VERSION ""

NS_ :

BS_:

BU_:

BO_ 1038 ID_1038: 8 Vector__XXX
 SG_ electricalRPM_erpm : 7|32@0+ (1,0) [0|4294967295] "rpm" Vector__XXX
 SG_ dutyCycle_percent : 39|16@0+ (0.1,0) [0.0|6553.5] "%" Vector__XXX
 SG_ inputInverterVoltage_V : 55|16@0+ (1,0) [0|65535] "V" Vector__XXX

BO_ 1070 ID_1070: 8 Vector__XXX
 SG_ motorCurrentPeakToPeak_A : 7|16@0+ (0.1,0) [0.0|6553.5] "A" Vector__XXX
 SG_ batteryCurrent_A : 23|16@0+ (0.1,0) [0.0|6553.5] "A" Vector__XXX

BO_ 1102 ID_1102: 8 Vector__XXX
 SG_ ControllerTemp_C : 7|16@0+ (0.1,0) [0.0|6553.5] "C" Vector__XXX
 SG_ motorTemp_C : 23|16@0+ (0.1,0) [0.0|6553.5] "C" Vector__XXX
 SG_ faultCode : 39|8@0+ (1,0) [0|255] "" Vector__XXX

BO_ 1134 ID_1134: 8 Vector__XXX
 SG_ idPeakToPeak_A : 7|32@0+ (0.01,0) [0.0|42949672.95] "A" Vector__XXX
 SG_ iqPeakToPeak_A : 39|32@0+ (0.01,0) [0.0|42949672.95] "A" Vector__XXX

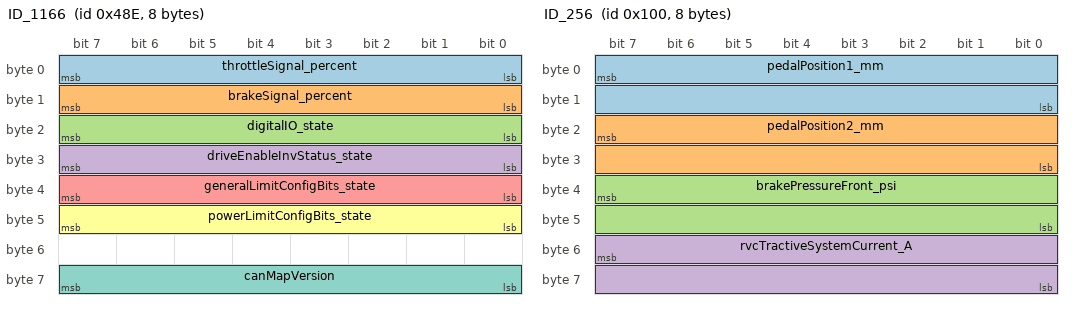
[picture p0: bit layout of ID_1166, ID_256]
BO_ 1166 ID_1166: 8 Vector__XXX
 SG_ throttleSignal_percent : 7|8@0+ (1,0) [0|255] "%" Vector__XXX
 SG_ brakeSignal_percent : 15|8@0+ (1,0) [0|255] "%" Vector__XXX
 SG_ digitalIO_state : 23|8@0+ (1,0) [0|255] "" Vector__XXX
 SG_ driveEnableInvStatus_state : 31|8@0+ (1,0) [0|255] "" Vector__XXX
 SG_ generalLimitConfigBits_state : 39|8@0+ (1,0) [0|255] "" Vector__XXX
 SG_ powerLimitConfigBits_state : 47|8@0+ (1,0) [0|255] "" Vector__XXX
 SG_ canMapVersion : 63|8@0+ (1,0) [0|255] "" Vector__XXX

BO_ 46 ID_46: 8 Vector__XXX
 SG_ desiredInvCurrentPeak_A : 7|16@0+ (0.1,0) [0.0|6553.5] "A" Vector__XXX

BO_ 270 ID_270: 8 Vector__XXX
 SG_ maxCurrentLimitPeak_A : 7|16@0+ (0.1,0) [0.0|6553.5] "A" Vector__XXX

BO_ 334 ID_334: 8 Vector__XXX
 SG_ maxDCCurrentLimit_A : 7|16@0+ (0.1,0) [0.0|6553.5] "A" Vector__XXX

BO_ 398 ID_398: 8 Vector__XXX
 SG_ driveEnable_state : 7|8@0+ (1,0) [0|255] "A" Vector__XXX

BO_ 256 ID_256: 8 Vector__XXX
 SG_ pedalPosition1_mm : 7|16@0+ (0.00610500611,0) [0.0|400.09157541885] "mm" Vector__XXX
 SG_ pedalPosition2_mm : 23|16@0+ (0.00610500611,0) [0.0|400.09157541885] "mm" Vector__XXX
 SG_ brakePressureFront_psi : 39|16@0+ (0.488400488,0) [0.0|32007.32598108] "psi" Vector__XXX
 SG_ rvcTractiveSystemCurrent_A : 55|16@0+ (0.00914627595,-18.727) [-18.727|580.67419438325] "A" Vector__XXX

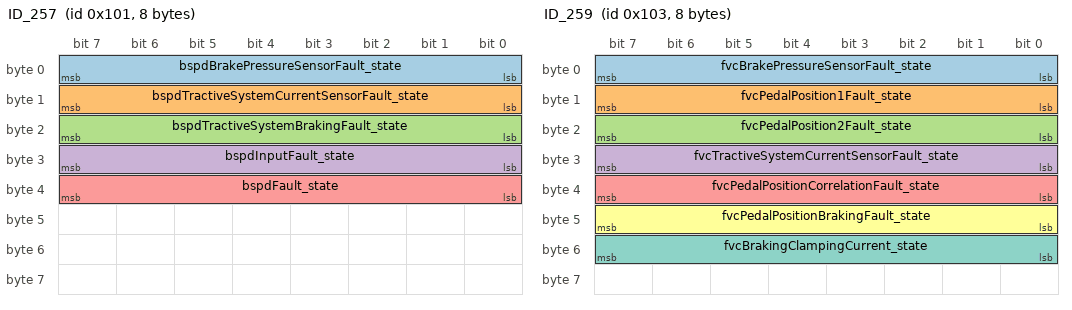
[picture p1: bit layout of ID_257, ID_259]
BO_ 257 ID_257: 8 Vector__XXX
 SG_ bspdBrakePressureSensorFault_state : 7|8@0+ (1,0) [0|255] "" Vector__XXX
 SG_ bspdTractiveSystemCurrentSensorFault_state : 15|8@0+ (1,0) [0|255] "" Vector__XXX
 SG_ bspdTractiveSystemBrakingFault_state : 23|8@0+ (1,0) [0|255] "" Vector__XXX
 SG_ bspdInputFault_state : 31|8@0+ (1,0) [0|255] "" Vector__XXX
 SG_ bspdFault_state : 39|8@0+ (1,0) [0|255] "" Vector__XXX

BO_ 258 ID_258: 8 Vector__XXX
 SG_ pedalPosition1_percent : 7|16@0+ (0.1,0) [0.0|6553.5] "%" Vector__XXX
 SG_ pedalPosition2_percent : 23|16@0+ (0.1,0) [0.0|6553.5] "%" Vector__XXX
 SG_ rideHeightFront_mm : 39|16@0+ (1,0) [0|65535] "mm" Vector__XXX

BO_ 259 ID_259: 8 Vector__XXX
 SG_ fvcBrakePressureSensorFault_state : 7|8@0+ (1,0) [0|255] "" Vector__XXX
 SG_ fvcPedalPosition1Fault_state : 15|8@0+ (1,0) [0|255] "" Vector__XXX
 SG_ fvcPedalPosition2Fault_state : 23|8@0+ (1,0) [0|255] "" Vector__XXX
 SG_ fvcTractiveSystemCurrentSensorFault_state : 31|8@0+ (1,0) [0|255] "" Vector__XXX
 SG_ fvcPedalPositionCorrelationFault_state : 39|8@0+ (1,0) [0|255] "" Vector__XXX
 SG_ fvcPedalPositionBrakingFault_state : 47|8@0+ (1,0) [0|255] "" Vector__XXX
 SG_ fvcBrakingClampingCurrent_state : 55|8@0+ (1,0) [0|255] "" Vector__XXX

BO_ 260 ID_260: 8 Vector__XXX
 SG_ coolantPumpPressure_psi : 7|16@0+ (0.0244200244,0) [0.0|1600.3662990540001] "psi" Vector__XXX
 SG_ coolantFanPower_percent : 23|8@0+ (1,0) [0|255] "%" Vector__XXX
 SG_ coolantPumpPower_percent : 31|8@0+ (1,0) [0|255] "%" Vector__XXX

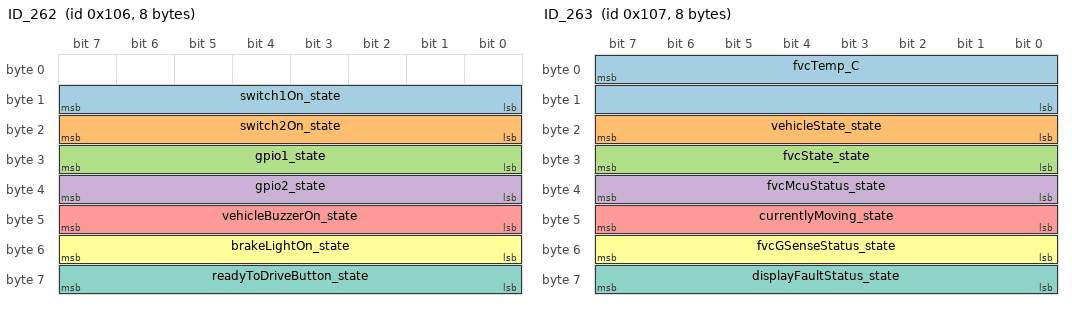
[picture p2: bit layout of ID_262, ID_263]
BO_ 262 ID_262: 8 Vector__XXX
 SG_ switch1On_state : 15|8@0+ (1,0) [0|255] "" Vector__XXX
 SG_ switch2On_state : 23|8@0+ (1,0) [0|255] "" Vector__XXX
 SG_ gpio1_state : 31|8@0+ (1,0) [0|255] "" Vector__XXX
 SG_ gpio2_state : 39|8@0+ (1,0) [0|255] "" Vector__XXX
 SG_ vehicleBuzzerOn_state : 47|8@0+ (1,0) [0|255] "" Vector__XXX
 SG_ brakeLightOn_state : 55|8@0+ (1,0) [0|255] "" Vector__XXX
 SG_ readyToDriveButton_state : 63|8@0+ (1,0) [0|255] "" Vector__XXX

BO_ 263 ID_263: 8 Vector__XXX
 SG_ fvcTemp_C : 7|16@0+ (0.1,0) [0.0|6553.5] "C" Vector__XXX
 SG_ vehicleState_state : 23|8@0+ (1,0) [0|255] "" Vector__XXX
 SG_ fvcState_state : 31|8@0+ (1,0) [0|255] "" Vector__XXX
 SG_ fvcMcuStatus_state : 39|8@0+ (1,0) [0|255] "" Vector__XXX
 SG_ currentlyMoving_state : 47|8@0+ (1,0) [0|255] "" Vector__XXX
 SG_ fvcGSenseStatus_state : 55|8@0+ (1,0) [0|255] "" Vector__XXX
 SG_ displayFaultStatus_state : 63|8@0+ (1,0) [0|255] "" Vector__XXX

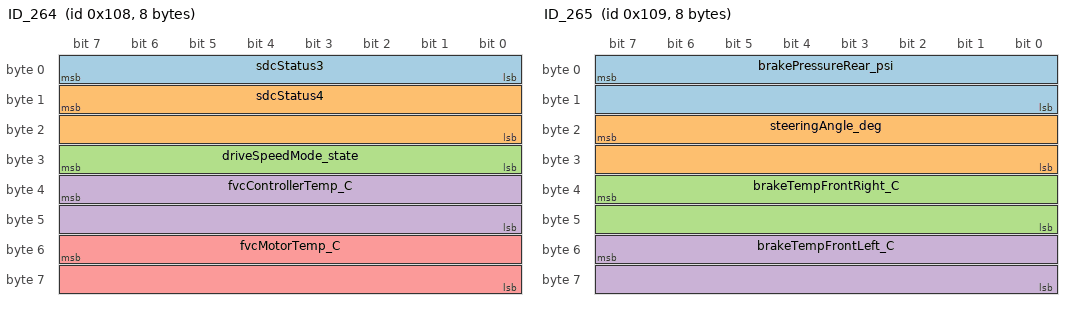
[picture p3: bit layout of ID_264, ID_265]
BO_ 264 ID_264: 8 Vector__XXX
 SG_ sdcStatus3 : 7|8@0+ (1,0) [0|255] "" Vector__XXX
 SG_ sdcStatus4 : 15|16@0+ (1,0) [0|65535] "" Vector__XXX
 SG_ driveSpeedMode_state : 31|8@0+ (1,0) [0|255] "" Vector__XXX
 SG_ fvcControllerTemp_C : 39|16@0+ (1,0) [0|65535] "C" Vector__XXX
 SG_ fvcMotorTemp_C : 55|16@0+ (1,0) [0|65535] "C" Vector__XXX

BO_ 265 ID_265: 8 Vector__XXX
 SG_ brakePressureRear_psi : 7|16@0+ (0.488400488,0) [0.0|32007.32598108] "psi" Vector__XXX
 SG_ steeringAngle_deg : 23|16@0+ (0.01,0) [0.0|655.35] "deg" Vector__XXX
 SG_ brakeTempFrontRight_C : 39|16@0+ (0.195360195,0) [0.0|12802.930379324998] "C" Vector__XXX
 SG_ brakeTempFrontLeft_C : 55|16@0+ (0.195360195,0) [0.0|12802.930379324998] "C" Vector__XXX

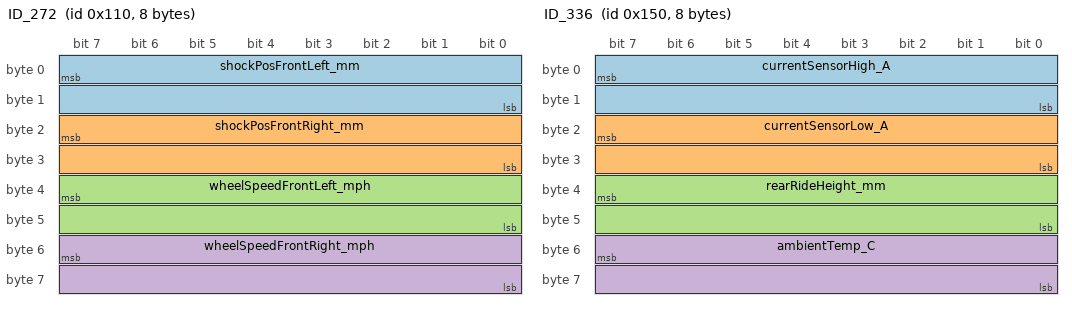
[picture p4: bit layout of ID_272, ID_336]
BO_ 272 ID_272: 8 Vector__XXX
 SG_ shockPosFrontLeft_mm : 7|16@0+ (0.01221001221,0) [0.0|800.18315018235] "mm" Vector__XXX
 SG_ shockPosFrontRight_mm : 23|16@0+ (0.01221001221,0) [0.0|800.18315018235] "mm" Vector__XXX
 SG_ wheelSpeedFrontLeft_mph : 39|16@0+ (0.01,0) [0.0|655.35] "mph" Vector__XXX
 SG_ wheelSpeedFrontRight_mph : 55|16@0+ (0.01,0) [0.0|655.35] "mph" Vector__XXX

BO_ 273 ID_273: 8 Vector__XXX
 SG_ pittoTubePressure_psi : 7|16@0+ (0.01,0) [0.0|655.35] "psi" Vector__XXX

BO_ 288 ID_288: 8 Vector__XXX
 SG_ fvcPowerCycleNeeded : 7|8@0+ (1,0) [0|255] "" Vector__XXX

BO_ 336 ID_336: 8 Vector__XXX
 SG_ currentSensorHigh_A : 7|16@0+ (0.1,-1000) [-1000.0|5553.5] "V" Vector__XXX
 SG_ currentSensorLow_A : 23|16@0+ (0.01,-100) [-100.0|555.35] "V" Vector__XXX
 SG_ rearRideHeight_mm : 39|16@0+ (1,0) [0|65535] "mm" Vector__XXX
 SG_ ambientTemp_C : 55|16@0+ (1,0) [0|65535] "C" Vector__XXX

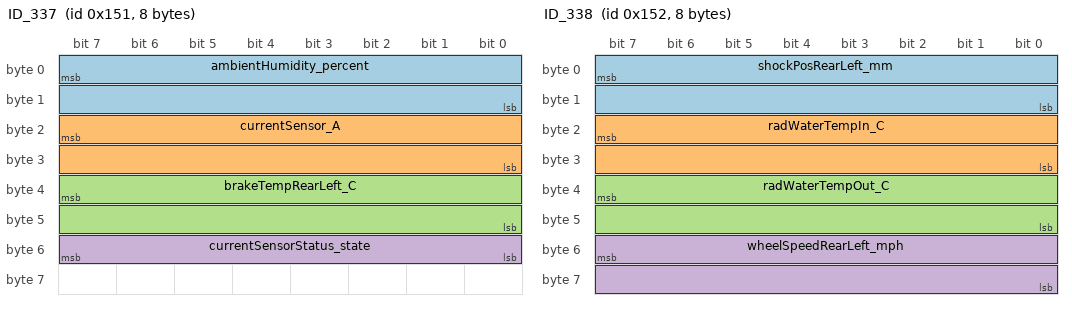
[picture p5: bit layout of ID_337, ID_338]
BO_ 337 ID_337: 8 Vector__XXX
 SG_ ambientHumidity_percent : 7|16@0+ (0.00152590218,0) [0.0|99.99999936629999] "%" Vector__XXX
 SG_ currentSensor_A : 23|16@0+ (0.01414511329,75) [75.0|1001.99999946015] "A" Vector__XXX
 SG_ brakeTempRearLeft_C : 39|16@0+ (0.195360195,0) [0.0|12802.930379324998] "C" Vector__XXX
 SG_ currentSensorStatus_state : 55|8@0+ (1,0) [0|255] "A" Vector__XXX

BO_ 338 ID_338: 8 Vector__XXX
 SG_ shockPosRearLeft_mm : 7|16@0+ (0.01221001221,0) [0.0|800.18315018235] "mm" Vector__XXX
 SG_ radWaterTempIn_C : 23|16@0+ (0.0488400488,0) [0.0|3200.7325981080003] "C" Vector__XXX
 SG_ radWaterTempOut_C : 39|16@0+ (0.0488400488,0) [0.0|3200.7325981080003] "C" Vector__XXX
 SG_ wheelSpeedRearLeft_mph : 55|16@0+ (0.002288853283971548,0) [0.0|149.9999999650754] "mph" Vector__XXX

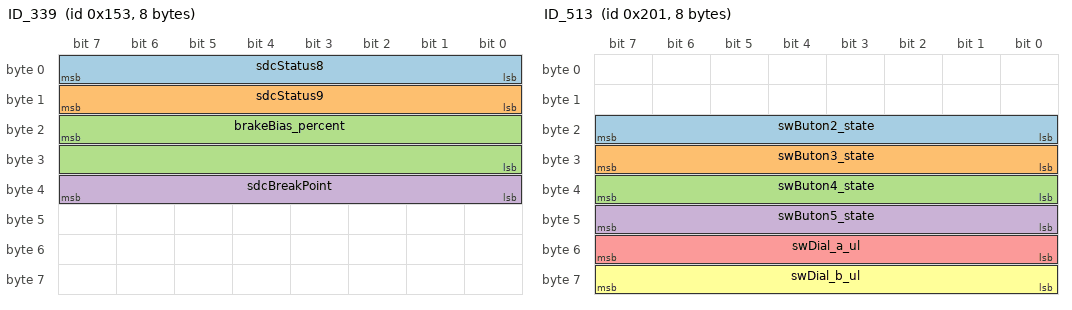
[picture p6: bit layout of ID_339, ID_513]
BO_ 339 ID_339: 8 Vector__XXX
 SG_ sdcStatus8 : 7|8@0+ (1,0) [0|255] "" Vector__XXX
 SG_ sdcStatus9 : 15|8@0+ (1,0) [0|255] "" Vector__XXX
 SG_ brakeBias_percent : 23|16@0+ (1,0) [0|65535] "" Vector__XXX
 SG_ sdcBreakPoint : 39|8@0+ (1,0) [0|255] "" Vector__XXX

BO_ 340 ID_340: 8 Vector__XXX
 SG_ brakeTempRearRight_C : 7|16@0+ (0.195360195,0) [0.0|12802.930379324998] "C" Vector__XXX
 SG_ shockPosRearRight_mm : 23|16@0+ (0.01221001221,0) [0.0|800.18315018235] "mm" Vector__XXX
 SG_ wheelSpeedRearRight_mph : 39|16@0+ (0.002288853283971548,0) [0.0|149.9999999650754] "mph" Vector__XXX

BO_ 341 ID_341: 8 Vector__XXX
 SG_ sdcStatus5 : 7|8@0+ (1,0) [0|255] "" Vector__XXX
 SG_ sdcStatus6 : 15|8@0+ (1,0) [0|255] "" Vector__XXX
 SG_ sdcStatus7 : 23|8@0+ (1,0) [0|255] "" Vector__XXX

BO_ 512 ID_512: 8 Vector__XXX
 SG_ swButon0_state : 39|8@0+ (1,0) [0|255] "" Vector__XXX
 SG_ swButon1_state : 47|8@0+ (1,0) [0|255] "" Vector__XXX
 SG_ displayPage_state : 55|8@0+ (1,0) [0|255] "" Vector__XXX

BO_ 513 ID_513: 8 Vector__XXX
 SG_ swButon2_state : 23|8@0+ (1,0) [0|255] "" Vector__XXX
 SG_ swButon3_state : 31|8@0+ (1,0) [0|255] "" Vector__XXX
 SG_ swButon4_state : 39|8@0+ (1,0) [0|255] "" Vector__XXX
 SG_ swButon5_state : 47|8@0+ (1,0) [0|255] "" Vector__XXX
 SG_ swDial_a_ul : 55|8@0+ (1,0) [0|255] "" Vector__XXX
 SG_ swDial_b_ul : 63|8@0+ (1,0) [0|255] "" Vector__XXX

BO_ 592 ID_592: 8 Vector__XXX
 SG_ fvcLatitude : 7|64@0+ (9.75781955236954e-18,0) [0.0|180.0] "deg" Vector__XXX

BO_ 593 ID_593: 8 Vector__XXX
 SG_ fvcLongitude : 7|64@0+ (1.951563910473908e-17,0) [0.0|360.0] "deg" Vector__XXX

BO_ 594 ID_594: 8 Vector__XXX
 SG_ fvcAltitude : 7|64@0+ (1e-06,0) [0.0|18446744073709.55] "m" Vector__XXX

BO_ 595 ID_595: 8 Vector__XXX
 SG_ fvcVelBodyX : 7|32@0+ (0.001,0) [0.0|4294967.295] "m/s" Vector__XXX
 SG_ fvcVelBodyY : 39|32@0+ (0.001,0) [0.0|4294967.295] "m/s" Vector__XXX

BO_ 596 ID_596: 8 Vector__XXX
 SG_ fvcYaw : 7|32@0+ (0.001,0) [0.0|4294967.295] "deg" Vector__XXX
 SG_ fvcPitch : 39|32@0+ (0.001,0) [0.0|4294967.295] "deg" Vector__XXX

BO_ 597 ID_597: 8 Vector__XXX
 SG_ fvcRoll : 7|32@0+ (0.001,0) [0.0|4294967.295] "deg" Vector__XXX
 SG_ fvcLinBodyAccZ : 39|32@0+ (0.001,0) [0.0|4294967.295] "m/s^2" Vector__XXX

BO_ 598 ID_598: 8 Vector__XXX
 SG_ fvcLinBodyAccX : 7|32@0+ (0.001,0) [0.0|4294967.295] "m/s^2" Vector__XXX
 SG_ fvcLinBodyAccY : 39|32@0+ (0.001,0) [0.0|4294967.295] "m/s^2" Vector__XXX

BO_ 599 ID_599: 8 Vector__XXX
 SG_ fvcQuatX : 7|32@0+ (1e-05,0) [0.0|42949.67295] "none" Vector__XXX
 SG_ fvcQuatY : 39|32@0+ (1e-05,0) [0.0|42949.67295] "none" Vector__XXX

BO_ 600 ID_600: 8 Vector__XXX
 SG_ fvcQuatZ : 7|32@0+ (1e-05,0) [0.0|42949.67295] "none" Vector__XXX
 SG_ fvcQuatS : 39|32@0+ (1e-05,0) [0.0|42949.67295] "none" Vector__XXX

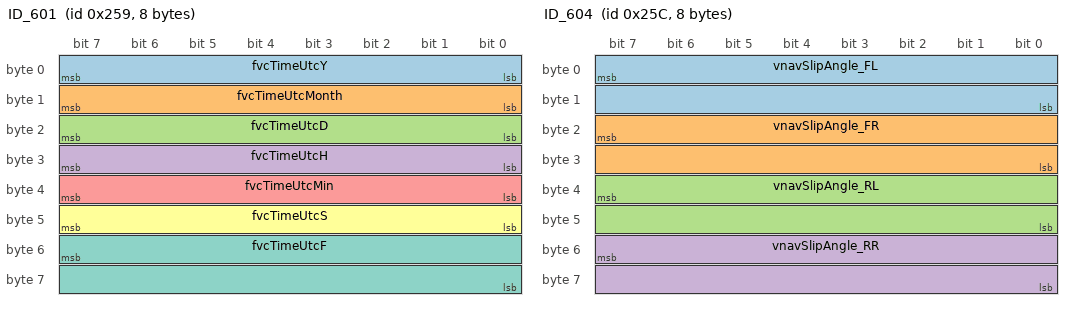
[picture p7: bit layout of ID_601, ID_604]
BO_ 601 ID_601: 8 Vector__XXX
 SG_ fvcTimeUtcY : 7|8@0+ (1,0) [0|255] "none" Vector__XXX
 SG_ fvcTimeUtcMonth : 15|8@0+ (1,0) [0|255] "none" Vector__XXX
 SG_ fvcTimeUtcD : 23|8@0+ (1,0) [0|255] "none" Vector__XXX
 SG_ fvcTimeUtcH : 31|8@0+ (1,0) [0|255] "none" Vector__XXX
 SG_ fvcTimeUtcMin : 39|8@0+ (1,0) [0|255] "none" Vector__XXX
 SG_ fvcTimeUtcS : 47|8@0+ (1,0) [0|255] "none" Vector__XXX
 SG_ fvcTimeUtcF : 55|16@0+ (1,0) [0|65535] "none" Vector__XXX

BO_ 602 ID_602: 8 Vector__XXX
 SG_ fvcGyroBodyX : 7|32@0+ (0.001,0) [0.0|4294967.295] "deg/s" Vector__XXX
 SG_ fvcGyroBodyY : 39|32@0+ (0.001,0) [0.0|4294967.295] "deg/s" Vector__XXX

BO_ 603 ID_603: 8 Vector__XXX
 SG_ fvcGyroBodyZ : 7|32@0+ (0.001,0) [0.0|4294967.295] "deg/s" Vector__XXX
 SG_ fvcINS_status : 39|16@0+ (1,0) [0|65535] "none" Vector__XXX

BO_ 604 ID_604: 8 Vector__XXX
 SG_ vnavSlipAngle_FL : 7|16@0+ (0.001,0) [0.0|65.535] "deg" Vector__XXX
 SG_ vnavSlipAngle_FR : 23|16@0+ (0.001,0) [0.0|65.535] "deg" Vector__XXX
 SG_ vnavSlipAngle_RL : 39|16@0+ (0.001,0) [0.0|65.535] "deg" Vector__XXX
 SG_ vnavSlipAngle_RR : 55|16@0+ (0.001,0) [0.0|65.535] "deg" Vector__XXX

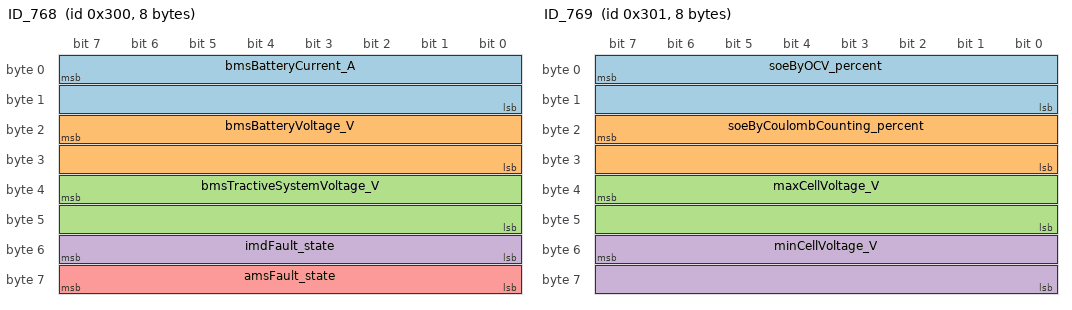
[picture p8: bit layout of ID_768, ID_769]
BO_ 768 ID_768: 8 Vector__XXX
 SG_ bmsBatteryCurrent_A : 7|16@0+ (0.01,-300) [-300.0|355.35] "A" Vector__XXX
 SG_ bmsBatteryVoltage_V : 23|16@0+ (0.1,0) [0.0|6553.5] "V" Vector__XXX
 SG_ bmsTractiveSystemVoltage_V : 39|16@0+ (0.1,0) [0.0|6553.5] "V" Vector__XXX
 SG_ imdFault_state : 55|8@0+ (1,0) [0|255] "" Vector__XXX
 SG_ amsFault_state : 63|8@0+ (1,0) [0|255] "" Vector__XXX

BO_ 769 ID_769: 8 Vector__XXX
 SG_ soeByOCV_percent : 7|16@0+ (0.01,0) [0.0|655.35] "%" Vector__XXX
 SG_ soeByCoulombCounting_percent : 23|16@0+ (0.01,0) [0.0|655.35] "%" Vector__XXX
 SG_ maxCellVoltage_V : 39|16@0+ (0.01,0) [0.0|655.35] "V" Vector__XXX
 SG_ minCellVoltage_V : 55|16@0+ (0.01,0) [0.0|655.35] "V" Vector__XXX

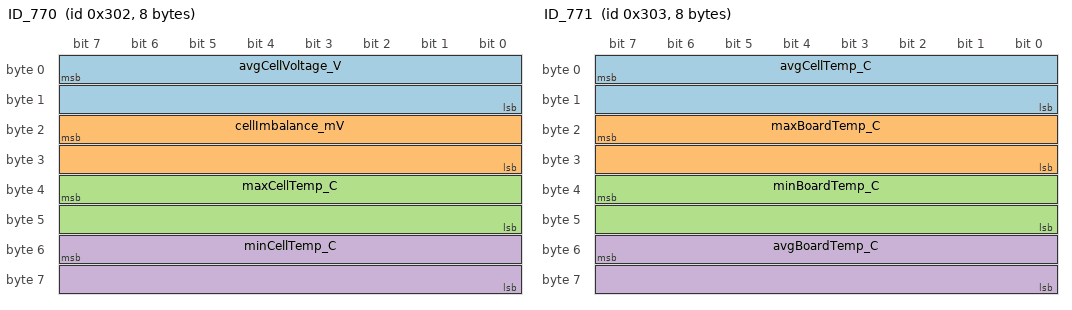
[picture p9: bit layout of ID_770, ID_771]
BO_ 770 ID_770: 8 Vector__XXX
 SG_ avgCellVoltage_V : 7|16@0+ (0.01,0) [0.0|655.35] "V" Vector__XXX
 SG_ cellImbalance_mV : 23|16@0+ (0.1,0) [0.0|6553.5] "mV" Vector__XXX
 SG_ maxCellTemp_C : 39|16@0+ (0.1,-40) [-40.0|6513.5] "C" Vector__XXX
 SG_ minCellTemp_C : 55|16@0+ (0.1,-40) [-40.0|6513.5] "C" Vector__XXX

BO_ 771 ID_771: 8 Vector__XXX
 SG_ avgCellTemp_C : 7|16@0+ (0.1,-40) [-40.0|6513.5] "C" Vector__XXX
 SG_ maxBoardTemp_C : 23|16@0+ (0.1,-40) [-40.0|6513.5] "C" Vector__XXX
 SG_ minBoardTemp_C : 39|16@0+ (0.1,-40) [-40.0|6513.5] "C" Vector__XXX
 SG_ avgBoardTemp_C : 55|16@0+ (0.1,-40) [-40.0|6513.5] "C" Vector__XXX

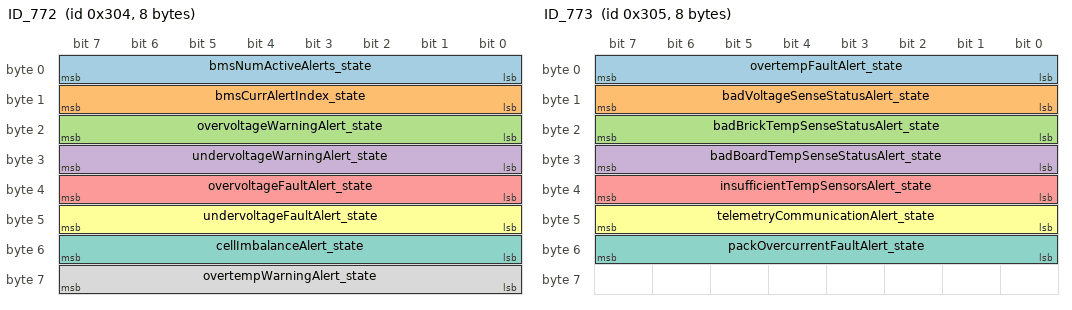
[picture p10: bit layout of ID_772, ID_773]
BO_ 772 ID_772: 8 Vector__XXX
 SG_ bmsNumActiveAlerts_state : 7|8@0+ (1,0) [0|255] "" Vector__XXX
 SG_ bmsCurrAlertIndex_state : 15|8@0+ (1,0) [0|255] "" Vector__XXX
 SG_ overvoltageWarningAlert_state : 23|8@0+ (1,0) [0|255] "" Vector__XXX
 SG_ undervoltageWarningAlert_state : 31|8@0+ (1,0) [0|255] "" Vector__XXX
 SG_ overvoltageFaultAlert_state : 39|8@0+ (1,0) [0|255] "" Vector__XXX
 SG_ undervoltageFaultAlert_state : 47|8@0+ (1,0) [0|255] "" Vector__XXX
 SG_ cellImbalanceAlert_state : 55|8@0+ (1,0) [0|255] "" Vector__XXX
 SG_ overtempWarningAlert_state : 63|8@0+ (1,0) [0|255] "" Vector__XXX

BO_ 773 ID_773: 8 Vector__XXX
 SG_ overtempFaultAlert_state : 7|8@0+ (1,0) [0|255] "" Vector__XXX
 SG_ badVoltageSenseStatusAlert_state : 15|8@0+ (1,0) [0|255] "" Vector__XXX
 SG_ badBrickTempSenseStatusAlert_state : 23|8@0+ (1,0) [0|255] "" Vector__XXX
 SG_ badBoardTempSenseStatusAlert_state : 31|8@0+ (1,0) [0|255] "" Vector__XXX
 SG_ insufficientTempSensorsAlert_state : 39|8@0+ (1,0) [0|255] "" Vector__XXX
 SG_ telemetryCommunicationAlert_state : 47|8@0+ (1,0) [0|255] "" Vector__XXX
 SG_ packOvercurrentFaultAlert_state : 55|8@0+ (1,0) [0|255] "" Vector__XXX

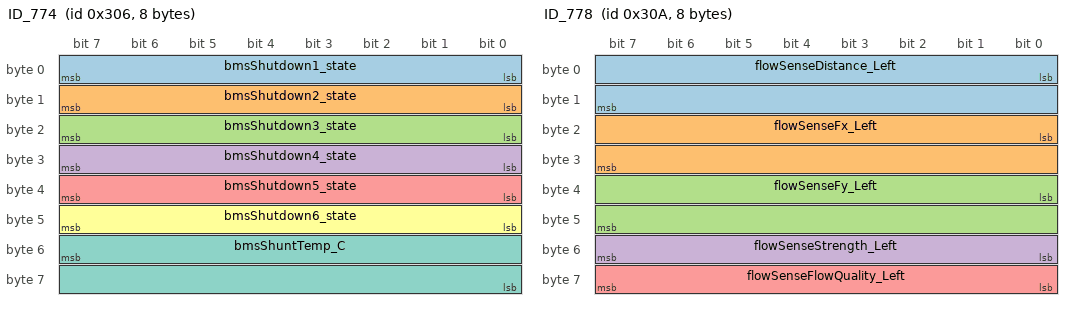
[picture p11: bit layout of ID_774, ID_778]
BO_ 774 ID_774: 8 Vector__XXX
 SG_ bmsShutdown1_state : 7|8@0+ (1,0) [0|255] "" Vector__XXX
 SG_ bmsShutdown2_state : 15|8@0+ (1,0) [0|255] "" Vector__XXX
 SG_ bmsShutdown3_state : 23|8@0+ (1,0) [0|255] "" Vector__XXX
 SG_ bmsShutdown4_state : 31|8@0+ (1,0) [0|255] "" Vector__XXX
 SG_ bmsShutdown5_state : 39|8@0+ (1,0) [0|255] "" Vector__XXX
 SG_ bmsShutdown6_state : 47|8@0+ (1,0) [0|255] "" Vector__XXX
 SG_ bmsShuntTemp_C : 55|16@0+ (0.1,-40) [-40.0|6513.5] "C" Vector__XXX

BO_ 778 ID_778: 8 Vector__XXX
 SG_ flowSenseDistance_Left : 0|16@1+ (1,0) [0|65535] "mm" Vector__XXX
 SG_ flowSenseFx_Left : 16|16@1+ (1,0) [0|65535] "cm/s" Vector__XXX
 SG_ flowSenseFy_Left : 32|16@1+ (1,0) [0|65535] "cm/s" Vector__XXX
 SG_ flowSenseStrength_Left : 48|8@1+ (1,0) [0|255] "" Vector__XXX
 SG_ flowSenseFlowQuality_Left : 56|8@1+ (1,0) [0|255] "" Vector__XXX

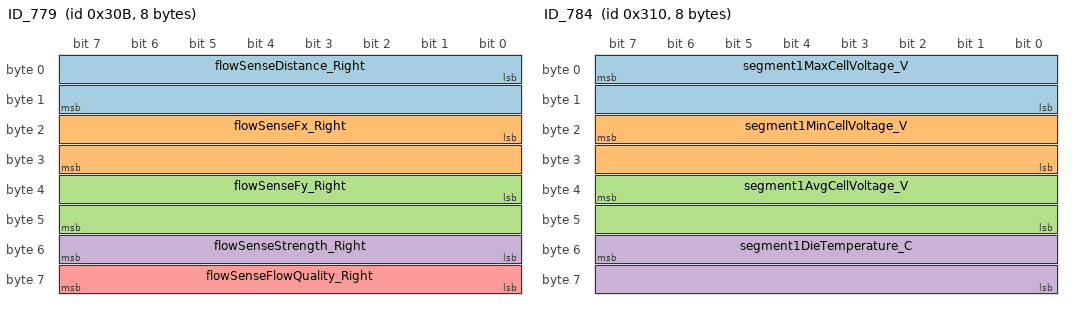
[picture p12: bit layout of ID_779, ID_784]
BO_ 779 ID_779: 8 Vector__XXX
 SG_ flowSenseDistance_Right : 0|16@1+ (1,0) [0|65535] "mm" Vector__XXX
 SG_ flowSenseFx_Right : 16|16@1+ (1,0) [0|65535] "cm/s" Vector__XXX
 SG_ flowSenseFy_Right : 32|16@1+ (1,0) [0|65535] "cm/s" Vector__XXX
 SG_ flowSenseStrength_Right : 48|8@1+ (1,0) [0|255] "" Vector__XXX
 SG_ flowSenseFlowQuality_Right : 56|8@1+ (1,0) [0|255] "" Vector__XXX

BO_ 784 ID_784: 8 Vector__XXX
 SG_ segment1MaxCellVoltage_V : 7|16@0+ (0.001,0) [0.0|65.535] "V" Vector__XXX
 SG_ segment1MinCellVoltage_V : 23|16@0+ (0.001,0) [0.0|65.535] "V" Vector__XXX
 SG_ segment1AvgCellVoltage_V : 39|16@0+ (0.001,0) [0.0|65.535] "V" Vector__XXX
 SG_ segment1DieTemperature_C : 55|16@0+ (0.1,-40) [-40.0|6513.5] "C" Vector__XXX

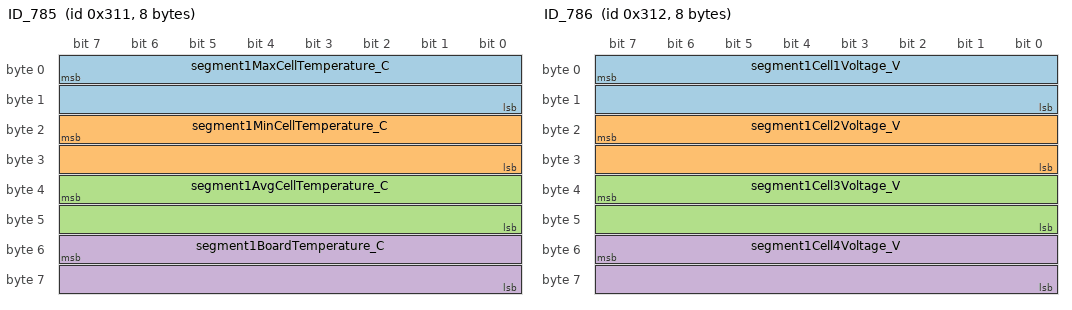
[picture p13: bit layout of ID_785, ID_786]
BO_ 785 ID_785: 8 Vector__XXX
 SG_ segment1MaxCellTemperature_C : 7|16@0+ (0.1,-40) [-40.0|6513.5] "C" Vector__XXX
 SG_ segment1MinCellTemperature_C : 23|16@0+ (0.1,-40) [-40.0|6513.5] "C" Vector__XXX
 SG_ segment1AvgCellTemperature_C : 39|16@0+ (0.1,-40) [-40.0|6513.5] "C" Vector__XXX
 SG_ segment1BoardTemperature_C : 55|16@0+ (0.1,-40) [-40.0|6513.5] "C" Vector__XXX

BO_ 786 ID_786: 8 Vector__XXX
 SG_ segment1Cell1Voltage_V : 7|16@0+ (0.001,0) [0.0|65.535] "V" Vector__XXX
 SG_ segment1Cell2Voltage_V : 23|16@0+ (0.001,0) [0.0|65.535] "V" Vector__XXX
 SG_ segment1Cell3Voltage_V : 39|16@0+ (0.001,0) [0.0|65.535] "V" Vector__XXX
 SG_ segment1Cell4Voltage_V : 55|16@0+ (0.001,0) [0.0|65.535] "V" Vector__XXX

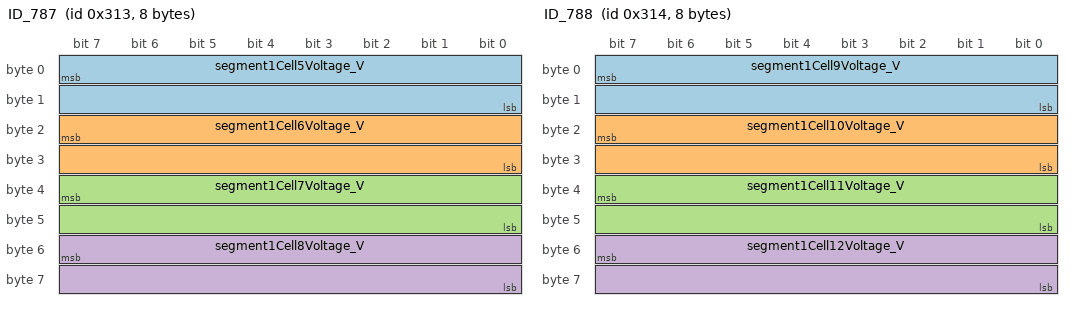
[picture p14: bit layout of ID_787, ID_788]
BO_ 787 ID_787: 8 Vector__XXX
 SG_ segment1Cell5Voltage_V : 7|16@0+ (0.001,0) [0.0|65.535] "V" Vector__XXX
 SG_ segment1Cell6Voltage_V : 23|16@0+ (0.001,0) [0.0|65.535] "V" Vector__XXX
 SG_ segment1Cell7Voltage_V : 39|16@0+ (0.001,0) [0.0|65.535] "V" Vector__XXX
 SG_ segment1Cell8Voltage_V : 55|16@0+ (0.001,0) [0.0|65.535] "V" Vector__XXX

BO_ 788 ID_788: 8 Vector__XXX
 SG_ segment1Cell9Voltage_V : 7|16@0+ (0.001,0) [0.0|65.535] "V" Vector__XXX
 SG_ segment1Cell10Voltage_V : 23|16@0+ (0.001,0) [0.0|65.535] "V" Vector__XXX
 SG_ segment1Cell11Voltage_V : 39|16@0+ (0.001,0) [0.0|65.535] "V" Vector__XXX
 SG_ segment1Cell12Voltage_V : 55|16@0+ (0.001,0) [0.0|65.535] "V" Vector__XXX

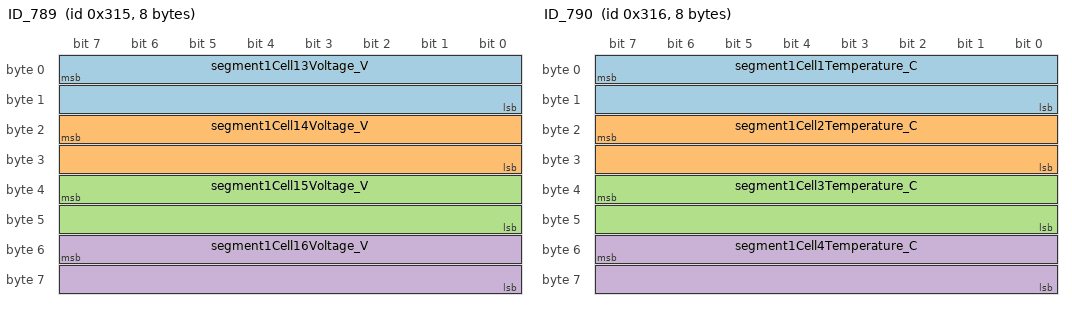
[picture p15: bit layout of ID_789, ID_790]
BO_ 789 ID_789: 8 Vector__XXX
 SG_ segment1Cell13Voltage_V : 7|16@0+ (0.001,0) [0.0|65.535] "V" Vector__XXX
 SG_ segment1Cell14Voltage_V : 23|16@0+ (0.001,0) [0.0|65.535] "V" Vector__XXX
 SG_ segment1Cell15Voltage_V : 39|16@0+ (0.001,0) [0.0|65.535] "V" Vector__XXX
 SG_ segment1Cell16Voltage_V : 55|16@0+ (0.001,0) [0.0|65.535] "V" Vector__XXX

BO_ 790 ID_790: 8 Vector__XXX
 SG_ segment1Cell1Temperature_C : 7|16@0+ (0.1,-40) [-40.0|6513.5] "C" Vector__XXX
 SG_ segment1Cell2Temperature_C : 23|16@0+ (0.1,-40) [-40.0|6513.5] "C" Vector__XXX
 SG_ segment1Cell3Temperature_C : 39|16@0+ (0.1,-40) [-40.0|6513.5] "C" Vector__XXX
 SG_ segment1Cell4Temperature_C : 55|16@0+ (0.1,-40) [-40.0|6513.5] "C" Vector__XXX

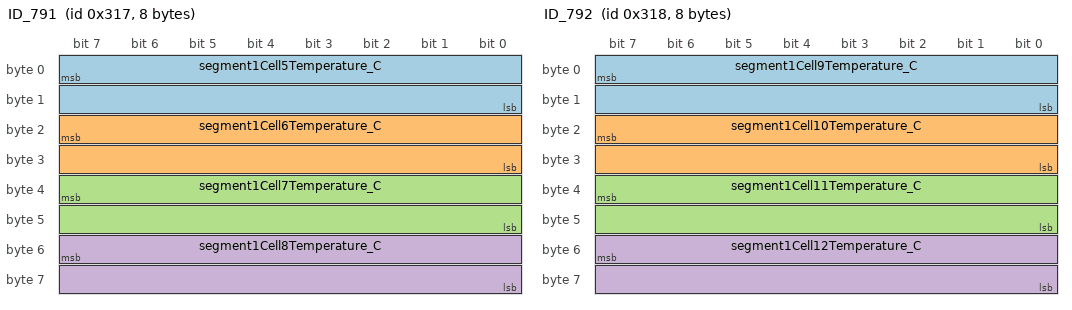
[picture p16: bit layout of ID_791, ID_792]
BO_ 791 ID_791: 8 Vector__XXX
 SG_ segment1Cell5Temperature_C : 7|16@0+ (0.1,-40) [-40.0|6513.5] "C" Vector__XXX
 SG_ segment1Cell6Temperature_C : 23|16@0+ (0.1,-40) [-40.0|6513.5] "C" Vector__XXX
 SG_ segment1Cell7Temperature_C : 39|16@0+ (0.1,-40) [-40.0|6513.5] "C" Vector__XXX
 SG_ segment1Cell8Temperature_C : 55|16@0+ (0.1,-40) [-40.0|6513.5] "C" Vector__XXX

BO_ 792 ID_792: 8 Vector__XXX
 SG_ segment1Cell9Temperature_C : 7|16@0+ (0.1,-40) [-40.0|6513.5] "C" Vector__XXX
 SG_ segment1Cell10Temperature_C : 23|16@0+ (0.1,-40) [-40.0|6513.5] "C" Vector__XXX
 SG_ segment1Cell11Temperature_C : 39|16@0+ (0.1,-40) [-40.0|6513.5] "C" Vector__XXX
 SG_ segment1Cell12Temperature_C : 55|16@0+ (0.1,-40) [-40.0|6513.5] "C" Vector__XXX

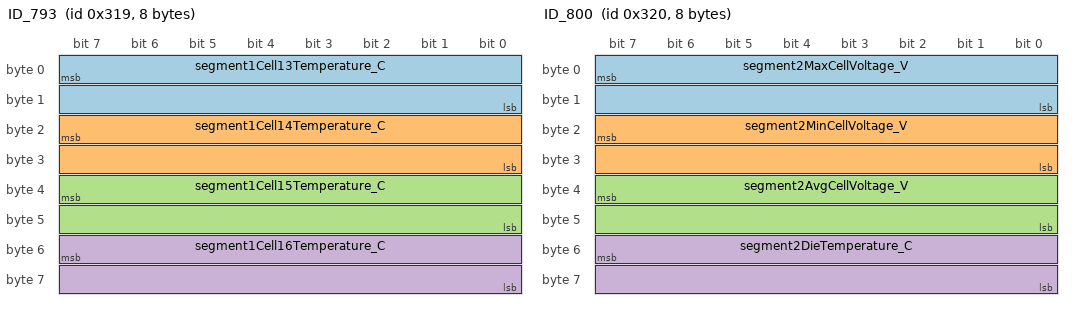
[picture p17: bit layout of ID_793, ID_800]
BO_ 793 ID_793: 8 Vector__XXX
 SG_ segment1Cell13Temperature_C : 7|16@0+ (0.1,-40) [-40.0|6513.5] "C" Vector__XXX
 SG_ segment1Cell14Temperature_C : 23|16@0+ (0.1,-40) [-40.0|6513.5] "C" Vector__XXX
 SG_ segment1Cell15Temperature_C : 39|16@0+ (0.1,-40) [-40.0|6513.5] "C" Vector__XXX
 SG_ segment1Cell16Temperature_C : 55|16@0+ (0.1,-40) [-40.0|6513.5] "C" Vector__XXX

BO_ 800 ID_800: 8 Vector__XXX
 SG_ segment2MaxCellVoltage_V : 7|16@0+ (0.001,0) [0.0|65.535] "V" Vector__XXX
 SG_ segment2MinCellVoltage_V : 23|16@0+ (0.001,0) [0.0|65.535] "V" Vector__XXX
 SG_ segment2AvgCellVoltage_V : 39|16@0+ (0.001,0) [0.0|65.535] "V" Vector__XXX
 SG_ segment2DieTemperature_C : 55|16@0+ (0.1,-40) [-40.0|6513.5] "C" Vector__XXX

BO_ 801 ID_801: 8 Vector__XXX
 SG_ segment2MaxCellTemperature_C : 7|16@0+ (0.1,-40) [-40.0|6513.5] "C" Vector__XXX
 SG_ segment2MinCellTemperature_C : 23|16@0+ (0.1,-40) [-40.0|6513.5] "C" Vector__XXX
 SG_ segment2AvgCellTemperature_C : 39|16@0+ (0.1,-40) [-40.0|6513.5] "C" Vector__XXX
 SG_ segment2BoardTemperature_C : 55|16@0+ (0.1,-40) [-40.0|6513.5] "C" Vector__XXX

BO_ 802 ID_802: 8 Vector__XXX
 SG_ segment2Cell1Voltage_V : 7|16@0+ (0.001,0) [0.0|65.535] "V" Vector__XXX
 SG_ segment2Cell2Voltage_V : 23|16@0+ (0.001,0) [0.0|65.535] "V" Vector__XXX
 SG_ segment2Cell3Voltage_V : 39|16@0+ (0.001,0) [0.0|65.535] "V" Vector__XXX
 SG_ segment2Cell4Voltage_V : 55|16@0+ (0.001,0) [0.0|65.535] "V" Vector__XXX

BO_ 803 ID_803: 8 Vector__XXX
 SG_ segment2Cell5Voltage_V : 7|16@0+ (0.001,0) [0.0|65.535] "V" Vector__XXX
 SG_ segment2Cell6Voltage_V : 23|16@0+ (0.001,0) [0.0|65.535] "V" Vector__XXX
 SG_ segment2Cell7Voltage_V : 39|16@0+ (0.001,0) [0.0|65.535] "V" Vector__XXX
 SG_ segment2Cell8Voltage_V : 55|16@0+ (0.001,0) [0.0|65.535] "V" Vector__XXX

BO_ 804 ID_804: 8 Vector__XXX
 SG_ segment2Cell9Voltage_V : 7|16@0+ (0.001,0) [0.0|65.535] "V" Vector__XXX
 SG_ segment2Cell10Voltage_V : 23|16@0+ (0.001,0) [0.0|65.535] "V" Vector__XXX
 SG_ segment2Cell11Voltage_V : 39|16@0+ (0.001,0) [0.0|65.535] "V" Vector__XXX
 SG_ segment2Cell12Voltage_V : 55|16@0+ (0.001,0) [0.0|65.535] "V" Vector__XXX

BO_ 805 ID_805: 8 Vector__XXX
 SG_ segment2Cell13Voltage_V : 7|16@0+ (0.001,0) [0.0|65.535] "V" Vector__XXX
 SG_ segment2Cell14Voltage_V : 23|16@0+ (0.001,0) [0.0|65.535] "V" Vector__XXX
 SG_ segment2Cell15Voltage_V : 39|16@0+ (0.001,0) [0.0|65.535] "V" Vector__XXX
 SG_ segment2Cell16Voltage_V : 55|16@0+ (0.001,0) [0.0|65.535] "V" Vector__XXX

BO_ 806 ID_806: 8 Vector__XXX
 SG_ segment2Cell1Temperature_C : 7|16@0+ (0.1,-40) [-40.0|6513.5] "C" Vector__XXX
 SG_ segment2Cell2Temperature_C : 23|16@0+ (0.1,-40) [-40.0|6513.5] "C" Vector__XXX
 SG_ segment2Cell3Temperature_C : 39|16@0+ (0.1,-40) [-40.0|6513.5] "C" Vector__XXX
 SG_ segment2Cell4Temperature_C : 55|16@0+ (0.1,-40) [-40.0|6513.5] "C" Vector__XXX

BO_ 807 ID_807: 8 Vector__XXX
 SG_ segment2Cell5Temperature_C : 7|16@0+ (0.1,-40) [-40.0|6513.5] "C" Vector__XXX
 SG_ segment2Cell6Temperature_C : 23|16@0+ (0.1,-40) [-40.0|6513.5] "C" Vector__XXX
 SG_ segment2Cell7Temperature_C : 39|16@0+ (0.1,-40) [-40.0|6513.5] "C" Vector__XXX
 SG_ segment2Cell8Temperature_C : 55|16@0+ (0.1,-40) [-40.0|6513.5] "C" Vector__XXX

BO_ 808 ID_808: 8 Vector__XXX
 SG_ segment2Cell9Temperature_C : 7|16@0+ (0.1,-40) [-40.0|6513.5] "C" Vector__XXX
 SG_ segment2Cell10Temperature_C : 23|16@0+ (0.1,-40) [-40.0|6513.5] "C" Vector__XXX
 SG_ segment2Cell11Temperature_C : 39|16@0+ (0.1,-40) [-40.0|6513.5] "C" Vector__XXX
 SG_ segment2Cell12Temperature_C : 55|16@0+ (0.1,-40) [-40.0|6513.5] "C" Vector__XXX

BO_ 809 ID_809: 8 Vector__XXX
 SG_ segment2Cell13Temperature_C : 7|16@0+ (0.1,-40) [-40.0|6513.5] "C" Vector__XXX
 SG_ segment2Cell14Temperature_C : 23|16@0+ (0.1,-40) [-40.0|6513.5] "C" Vector__XXX
 SG_ segment2Cell15Temperature_C : 39|16@0+ (0.1,-40) [-40.0|6513.5] "C" Vector__XXX
 SG_ segment2Cell16Temperature_C : 55|16@0+ (0.1,-40) [-40.0|6513.5] "C" Vector__XXX

BO_ 816 ID_816: 8 Vector__XXX
 SG_ segment3MaxCellVoltage_V : 7|16@0+ (0.001,0) [0.0|65.535] "V" Vector__XXX
 SG_ segment3MinCellVoltage_V : 23|16@0+ (0.001,0) [0.0|65.535] "V" Vector__XXX
 SG_ segment3AvgCellVoltage_V : 39|16@0+ (0.001,0) [0.0|65.535] "V" Vector__XXX
 SG_ segment3DieTemperature_C : 55|16@0+ (0.1,-40) [-40.0|6513.5] "C" Vector__XXX

BO_ 817 ID_817: 8 Vector__XXX
 SG_ segment3MaxCellTemperature_C : 7|16@0+ (0.1,-40) [-40.0|6513.5] "C" Vector__XXX
 SG_ segment3MinCellTemperature_C : 23|16@0+ (0.1,-40) [-40.0|6513.5] "C" Vector__XXX
 SG_ segment3AvgCellTemperature_C : 39|16@0+ (0.1,-40) [-40.0|6513.5] "C" Vector__XXX
 SG_ segment3BoardTemperature_C : 55|16@0+ (0.1,-40) [-40.0|6513.5] "C" Vector__XXX

BO_ 818 ID_818: 8 Vector__XXX
 SG_ segment3Cell1Voltage_V : 7|16@0+ (0.001,0) [0.0|65.535] "V" Vector__XXX
 SG_ segment3Cell2Voltage_V : 23|16@0+ (0.001,0) [0.0|65.535] "V" Vector__XXX
 SG_ segment3Cell3Voltage_V : 39|16@0+ (0.001,0) [0.0|65.535] "V" Vector__XXX
 SG_ segment3Cell4Voltage_V : 55|16@0+ (0.001,0) [0.0|65.535] "V" Vector__XXX

BO_ 819 ID_819: 8 Vector__XXX
 SG_ segment3Cell5Voltage_V : 7|16@0+ (0.001,0) [0.0|65.535] "V" Vector__XXX
 SG_ segment3Cell6Voltage_V : 23|16@0+ (0.001,0) [0.0|65.535] "V" Vector__XXX
 SG_ segment3Cell7Voltage_V : 39|16@0+ (0.001,0) [0.0|65.535] "V" Vector__XXX
 SG_ segment3Cell8Voltage_V : 55|16@0+ (0.001,0) [0.0|65.535] "V" Vector__XXX

BO_ 820 ID_820: 8 Vector__XXX
 SG_ segment3Cell9Voltage_V : 7|16@0+ (0.001,0) [0.0|65.535] "V" Vector__XXX
 SG_ segment3Cell10Voltage_V : 23|16@0+ (0.001,0) [0.0|65.535] "V" Vector__XXX
 SG_ segment3Cell11Voltage_V : 39|16@0+ (0.001,0) [0.0|65.535] "V" Vector__XXX
 SG_ segment3Cell12Voltage_V : 55|16@0+ (0.001,0) [0.0|65.535] "V" Vector__XXX

BO_ 821 ID_821: 8 Vector__XXX
 SG_ segment3Cell13Voltage_V : 7|16@0+ (0.001,0) [0.0|65.535] "V" Vector__XXX
 SG_ segment3Cell14Voltage_V : 23|16@0+ (0.001,0) [0.0|65.535] "V" Vector__XXX
 SG_ segment3Cell15Voltage_V : 39|16@0+ (0.001,0) [0.0|65.535] "V" Vector__XXX
 SG_ segment3Cell16Voltage_V : 55|16@0+ (0.001,0) [0.0|65.535] "V" Vector__XXX

BO_ 822 ID_822: 8 Vector__XXX
 SG_ segment3Cell1Temperature_C : 7|16@0+ (0.1,-40) [-40.0|6513.5] "C" Vector__XXX
 SG_ segment3Cell2Temperature_C : 23|16@0+ (0.1,-40) [-40.0|6513.5] "C" Vector__XXX
 SG_ segment3Cell3Temperature_C : 39|16@0+ (0.1,-40) [-40.0|6513.5] "C" Vector__XXX
 SG_ segment3Cell4Temperature_C : 55|16@0+ (0.1,-40) [-40.0|6513.5] "C" Vector__XXX

BO_ 823 ID_823: 8 Vector__XXX
 SG_ segment3Cell5Temperature_C : 7|16@0+ (0.1,-40) [-40.0|6513.5] "C" Vector__XXX
 SG_ segment3Cell6Temperature_C : 23|16@0+ (0.1,-40) [-40.0|6513.5] "C" Vector__XXX
 SG_ segment3Cell7Temperature_C : 39|16@0+ (0.1,-40) [-40.0|6513.5] "C" Vector__XXX
 SG_ segment3Cell8Temperature_C : 55|16@0+ (0.1,-40) [-40.0|6513.5] "C" Vector__XXX

BO_ 824 ID_824: 8 Vector__XXX
 SG_ segment3Cell9Temperature_C : 7|16@0+ (0.1,-40) [-40.0|6513.5] "C" Vector__XXX
 SG_ segment3Cell10Temperature_C : 23|16@0+ (0.1,-40) [-40.0|6513.5] "C" Vector__XXX
 SG_ segment3Cell11Temperature_C : 39|16@0+ (0.1,-40) [-40.0|6513.5] "C" Vector__XXX
 SG_ segment3Cell12Temperature_C : 55|16@0+ (0.1,-40) [-40.0|6513.5] "C" Vector__XXX

BO_ 825 ID_825: 8 Vector__XXX
 SG_ segment3Cell13Temperature_C : 7|16@0+ (0.1,-40) [-40.0|6513.5] "C" Vector__XXX
 SG_ segment3Cell14Temperature_C : 23|16@0+ (0.1,-40) [-40.0|6513.5] "C" Vector__XXX
 SG_ segment3Cell15Temperature_C : 39|16@0+ (0.1,-40) [-40.0|6513.5] "C" Vector__XXX
 SG_ segment3Cell16Temperature_C : 55|16@0+ (0.1,-40) [-40.0|6513.5] "C" Vector__XXX

BO_ 832 ID_832: 8 Vector__XXX
 SG_ segment4MaxCellVoltage_V : 7|16@0+ (0.001,0) [0.0|65.535] "V" Vector__XXX
 SG_ segment4MinCellVoltage_V : 23|16@0+ (0.001,0) [0.0|65.535] "V" Vector__XXX
 SG_ segment4AvgCellVoltage_V : 39|16@0+ (0.001,0) [0.0|65.535] "V" Vector__XXX
 SG_ segment4DieTemperature_C : 55|16@0+ (0.1,-40) [-40.0|6513.5] "C" Vector__XXX

BO_ 833 ID_833: 8 Vector__XXX
 SG_ segment4MaxCellTemperature_C : 7|16@0+ (0.1,-40) [-40.0|6513.5] "C" Vector__XXX
 SG_ segment4MinCellTemperature_C : 23|16@0+ (0.1,-40) [-40.0|6513.5] "C" Vector__XXX
 SG_ segment4AvgCellTemperature_C : 39|16@0+ (0.1,-40) [-40.0|6513.5] "C" Vector__XXX
 SG_ segment4BoardTemperature_C : 55|16@0+ (0.1,-40) [-40.0|6513.5] "C" Vector__XXX

BO_ 834 ID_834: 8 Vector__XXX
 SG_ segment4Cell1Voltage_V : 7|16@0+ (0.001,0) [0.0|65.535] "V" Vector__XXX
 SG_ segment4Cell2Voltage_V : 23|16@0+ (0.001,0) [0.0|65.535] "V" Vector__XXX
 SG_ segment4Cell3Voltage_V : 39|16@0+ (0.001,0) [0.0|65.535] "V" Vector__XXX
 SG_ segment4Cell4Voltage_V : 55|16@0+ (0.001,0) [0.0|65.535] "V" Vector__XXX

BO_ 835 ID_835: 8 Vector__XXX
 SG_ segment4Cell5Voltage_V : 7|16@0+ (0.001,0) [0.0|65.535] "V" Vector__XXX
 SG_ segment4Cell6Voltage_V : 23|16@0+ (0.001,0) [0.0|65.535] "V" Vector__XXX
 SG_ segment4Cell7Voltage_V : 39|16@0+ (0.001,0) [0.0|65.535] "V" Vector__XXX
 SG_ segment4Cell8Voltage_V : 55|16@0+ (0.001,0) [0.0|65.535] "V" Vector__XXX

BO_ 836 ID_836: 8 Vector__XXX
 SG_ segment4Cell9Voltage_V : 7|16@0+ (0.001,0) [0.0|65.535] "V" Vector__XXX
 SG_ segment4Cell10Voltage_V : 23|16@0+ (0.001,0) [0.0|65.535] "V" Vector__XXX
 SG_ segment4Cell11Voltage_V : 39|16@0+ (0.001,0) [0.0|65.535] "V" Vector__XXX
 SG_ segment4Cell12Voltage_V : 55|16@0+ (0.001,0) [0.0|65.535] "V" Vector__XXX

BO_ 837 ID_837: 8 Vector__XXX
 SG_ segment4Cell13Voltage_V : 7|16@0+ (0.001,0) [0.0|65.535] "V" Vector__XXX
 SG_ segment4Cell14Voltage_V : 23|16@0+ (0.001,0) [0.0|65.535] "V" Vector__XXX
 SG_ segment4Cell15Voltage_V : 39|16@0+ (0.001,0) [0.0|65.535] "V" Vector__XXX
 SG_ segment4Cell16Voltage_V : 55|16@0+ (0.001,0) [0.0|65.535] "V" Vector__XXX

BO_ 838 ID_838: 8 Vector__XXX
 SG_ segment4Cell1Temperature_C : 7|16@0+ (0.1,-40) [-40.0|6513.5] "C" Vector__XXX
 SG_ segment4Cell2Temperature_C : 23|16@0+ (0.1,-40) [-40.0|6513.5] "C" Vector__XXX
 SG_ segment4Cell3Temperature_C : 39|16@0+ (0.1,-40) [-40.0|6513.5] "C" Vector__XXX
 SG_ segment4Cell4Temperature_C : 55|16@0+ (0.1,-40) [-40.0|6513.5] "C" Vector__XXX

BO_ 839 ID_839: 8 Vector__XXX
 SG_ segment4Cell5Temperature_C : 7|16@0+ (0.1,-40) [-40.0|6513.5] "C" Vector__XXX
 SG_ segment4Cell6Temperature_C : 23|16@0+ (0.1,-40) [-40.0|6513.5] "C" Vector__XXX
 SG_ segment4Cell7Temperature_C : 39|16@0+ (0.1,-40) [-40.0|6513.5] "C" Vector__XXX
 SG_ segment4Cell8Temperature_C : 55|16@0+ (0.1,-40) [-40.0|6513.5] "C" Vector__XXX

BO_ 840 ID_840: 8 Vector__XXX
 SG_ segment4Cell9Temperature_C : 7|16@0+ (0.1,-40) [-40.0|6513.5] "C" Vector__XXX
 SG_ segment4Cell10Temperature_C : 23|16@0+ (0.1,-40) [-40.0|6513.5] "C" Vector__XXX
 SG_ segment4Cell11Temperature_C : 39|16@0+ (0.1,-40) [-40.0|6513.5] "C" Vector__XXX
 SG_ segment4Cell12Temperature_C : 55|16@0+ (0.1,-40) [-40.0|6513.5] "C" Vector__XXX

BO_ 841 ID_841: 8 Vector__XXX
 SG_ segment4Cell13Temperature_C : 7|16@0+ (0.1,-40) [-40.0|6513.5] "C" Vector__XXX
 SG_ segment4Cell14Temperature_C : 23|16@0+ (0.1,-40) [-40.0|6513.5] "C" Vector__XXX
 SG_ segment4Cell15Temperature_C : 39|16@0+ (0.1,-40) [-40.0|6513.5] "C" Vector__XXX
 SG_ segment4Cell16Temperature_C : 55|16@0+ (0.1,-40) [-40.0|6513.5] "C" Vector__XXX

BO_ 848 ID_848: 8 Vector__XXX
 SG_ segment5MaxCellVoltage_V : 7|16@0+ (0.001,0) [0.0|65.535] "V" Vector__XXX
 SG_ segment5MinCellVoltage_V : 23|16@0+ (0.001,0) [0.0|65.535] "V" Vector__XXX
 SG_ segment5AvgCellVoltage_V : 39|16@0+ (0.001,0) [0.0|65.535] "V" Vector__XXX
 SG_ segment5DieTemperature_C : 55|16@0+ (0.1,-40) [-40.0|6513.5] "C" Vector__XXX

BO_ 849 ID_849: 8 Vector__XXX
 SG_ segment5MaxCellTemperature_C : 7|16@0+ (0.1,-40) [-40.0|6513.5] "C" Vector__XXX
 SG_ segment5MinCellTemperature_C : 23|16@0+ (0.1,-40) [-40.0|6513.5] "C" Vector__XXX
 SG_ segment5AvgCellTemperature_C : 39|16@0+ (0.1,-40) [-40.0|6513.5] "C" Vector__XXX
 SG_ segment5BoardTemperature_C : 55|16@0+ (0.1,-40) [-40.0|6513.5] "C" Vector__XXX

BO_ 850 ID_850: 8 Vector__XXX
 SG_ segment5Cell1Voltage_V : 7|16@0+ (0.001,0) [0.0|65.535] "V" Vector__XXX
 SG_ segment5Cell2Voltage_V : 23|16@0+ (0.001,0) [0.0|65.535] "V" Vector__XXX
 SG_ segment5Cell3Voltage_V : 39|16@0+ (0.001,0) [0.0|65.535] "V" Vector__XXX
 SG_ segment5Cell4Voltage_V : 55|16@0+ (0.001,0) [0.0|65.535] "V" Vector__XXX

BO_ 851 ID_851: 8 Vector__XXX
 SG_ segment5Cell5Voltage_V : 7|16@0+ (0.001,0) [0.0|65.535] "V" Vector__XXX
 SG_ segment5Cell6Voltage_V : 23|16@0+ (0.001,0) [0.0|65.535] "V" Vector__XXX
 SG_ segment5Cell7Voltage_V : 39|16@0+ (0.001,0) [0.0|65.535] "V" Vector__XXX
 SG_ segment5Cell8Voltage_V : 55|16@0+ (0.001,0) [0.0|65.535] "V" Vector__XXX

BO_ 852 ID_852: 8 Vector__XXX
 SG_ segment5Cell9Voltage_V : 7|16@0+ (0.001,0) [0.0|65.535] "V" Vector__XXX
 SG_ segment5Cell10Voltage_V : 23|16@0+ (0.001,0) [0.0|65.535] "V" Vector__XXX
 SG_ segment5Cell11Voltage_V : 39|16@0+ (0.001,0) [0.0|65.535] "V" Vector__XXX
 SG_ segment5Cell12Voltage_V : 55|16@0+ (0.001,0) [0.0|65.535] "V" Vector__XXX

BO_ 853 ID_853: 8 Vector__XXX
 SG_ segment5Cell13Voltage_V : 7|16@0+ (0.001,0) [0.0|65.535] "V" Vector__XXX
 SG_ segment5Cell14Voltage_V : 23|16@0+ (0.001,0) [0.0|65.535] "V" Vector__XXX
 SG_ segment5Cell15Voltage_V : 39|16@0+ (0.001,0) [0.0|65.535] "V" Vector__XXX
 SG_ segment5Cell16Voltage_V : 55|16@0+ (0.001,0) [0.0|65.535] "V" Vector__XXX

BO_ 854 ID_854: 8 Vector__XXX
 SG_ segment5Cell1Temperature_C : 7|16@0+ (0.1,-40) [-40.0|6513.5] "C" Vector__XXX
 SG_ segment5Cell2Temperature_C : 23|16@0+ (0.1,-40) [-40.0|6513.5] "C" Vector__XXX
 SG_ segment5Cell3Temperature_C : 39|16@0+ (0.1,-40) [-40.0|6513.5] "C" Vector__XXX
 SG_ segment5Cell4Temperature_C : 55|16@0+ (0.1,-40) [-40.0|6513.5] "C" Vector__XXX

BO_ 855 ID_855: 8 Vector__XXX
 SG_ segment5Cell5Temperature_C : 7|16@0+ (0.1,-40) [-40.0|6513.5] "C" Vector__XXX
 SG_ segment5Cell6Temperature_C : 23|16@0+ (0.1,-40) [-40.0|6513.5] "C" Vector__XXX
 SG_ segment5Cell7Temperature_C : 39|16@0+ (0.1,-40) [-40.0|6513.5] "C" Vector__XXX
 SG_ segment5Cell8Temperature_C : 55|16@0+ (0.1,-40) [-40.0|6513.5] "C" Vector__XXX

BO_ 856 ID_856: 8 Vector__XXX
 SG_ segment5Cell9Temperature_C : 7|16@0+ (0.1,-40) [-40.0|6513.5] "C" Vector__XXX
 SG_ segment5Cell10Temperature_C : 23|16@0+ (0.1,-40) [-40.0|6513.5] "C" Vector__XXX
 SG_ segment5Cell11Temperature_C : 39|16@0+ (0.1,-40) [-40.0|6513.5] "C" Vector__XXX
 SG_ segment5Cell12Temperature_C : 55|16@0+ (0.1,-40) [-40.0|6513.5] "C" Vector__XXX

BO_ 857 ID_857: 8 Vector__XXX
 SG_ segment5Cell13Temperature_C : 7|16@0+ (0.1,-40) [-40.0|6513.5] "C" Vector__XXX
 SG_ segment5Cell14Temperature_C : 23|16@0+ (0.1,-40) [-40.0|6513.5] "C" Vector__XXX
 SG_ segment5Cell15Temperature_C : 39|16@0+ (0.1,-40) [-40.0|6513.5] "C" Vector__XXX
 SG_ segment5Cell16Temperature_C : 55|16@0+ (0.1,-40) [-40.0|6513.5] "C" Vector__XXX

BO_ 864 ID_864: 8 Vector__XXX
 SG_ segment6MaxCellVoltage_V : 7|16@0+ (0.001,0) [0.0|65.535] "V" Vector__XXX
 SG_ segment6MinCellVoltage_V : 23|16@0+ (0.001,0) [0.0|65.535] "V" Vector__XXX
 SG_ segment6AvgCellVoltage_V : 39|16@0+ (0.001,0) [0.0|65.535] "V" Vector__XXX
 SG_ segment6DieTemperature_C : 55|16@0+ (0.1,-40) [-40.0|6513.5] "C" Vector__XXX

BO_ 865 ID_865: 8 Vector__XXX
 SG_ segment6MaxCellTemperature_C : 7|16@0+ (0.1,-40) [-40.0|6513.5] "C" Vector__XXX
 SG_ segment6MinCellTemperature_C : 23|16@0+ (0.1,-40) [-40.0|6513.5] "C" Vector__XXX
 SG_ segment6AvgCellTemperature_C : 39|16@0+ (0.1,-40) [-40.0|6513.5] "C" Vector__XXX
 SG_ segment6BoardTemperature_C : 55|16@0+ (0.1,-40) [-40.0|6513.5] "C" Vector__XXX

BO_ 866 ID_866: 8 Vector__XXX
 SG_ segment6Cell1Voltage_V : 7|16@0+ (0.001,0) [0.0|65.535] "V" Vector__XXX
 SG_ segment6Cell2Voltage_V : 23|16@0+ (0.001,0) [0.0|65.535] "V" Vector__XXX
 SG_ segment6Cell3Voltage_V : 39|16@0+ (0.001,0) [0.0|65.535] "V" Vector__XXX
 SG_ segment6Cell4Voltage_V : 55|16@0+ (0.001,0) [0.0|65.535] "V" Vector__XXX

BO_ 867 ID_867: 8 Vector__XXX
 SG_ segment6Cell5Voltage_V : 7|16@0+ (0.001,0) [0.0|65.535] "V" Vector__XXX
 SG_ segment6Cell6Voltage_V : 23|16@0+ (0.001,0) [0.0|65.535] "V" Vector__XXX
 SG_ segment6Cell7Voltage_V : 39|16@0+ (0.001,0) [0.0|65.535] "V" Vector__XXX
 SG_ segment6Cell8Voltage_V : 55|16@0+ (0.001,0) [0.0|65.535] "V" Vector__XXX

BO_ 868 ID_868: 8 Vector__XXX
 SG_ segment6Cell9Voltage_V : 7|16@0+ (0.001,0) [0.0|65.535] "V" Vector__XXX
 SG_ segment6Cell10Voltage_V : 23|16@0+ (0.001,0) [0.0|65.535] "V" Vector__XXX
 SG_ segment6Cell11Voltage_V : 39|16@0+ (0.001,0) [0.0|65.535] "V" Vector__XXX
 SG_ segment6Cell12Voltage_V : 55|16@0+ (0.001,0) [0.0|65.535] "V" Vector__XXX

BO_ 869 ID_869: 8 Vector__XXX
 SG_ segment6Cell13Voltage_V : 7|16@0+ (0.001,0) [0.0|65.535] "V" Vector__XXX
 SG_ segment6Cell14Voltage_V : 23|16@0+ (0.001,0) [0.0|65.535] "V" Vector__XXX
 SG_ segment6Cell15Voltage_V : 39|16@0+ (0.001,0) [0.0|65.535] "V" Vector__XXX
 SG_ segment6Cell16Voltage_V : 55|16@0+ (0.001,0) [0.0|65.535] "V" Vector__XXX

BO_ 870 ID_870: 8 Vector__XXX
 SG_ segment6Cell1Temperature_C : 7|16@0+ (0.1,-40) [-40.0|6513.5] "C" Vector__XXX
 SG_ segment6Cell2Temperature_C : 23|16@0+ (0.1,-40) [-40.0|6513.5] "C" Vector__XXX
 SG_ segment6Cell3Temperature_C : 39|16@0+ (0.1,-40) [-40.0|6513.5] "C" Vector__XXX
 SG_ segment6Cell4Temperature_C : 55|16@0+ (0.1,-40) [-40.0|6513.5] "C" Vector__XXX

BO_ 871 ID_871: 8 Vector__XXX
 SG_ segment6Cell5Temperature_C : 7|16@0+ (0.1,-40) [-40.0|6513.5] "C" Vector__XXX
 SG_ segment6Cell6Temperature_C : 23|16@0+ (0.1,-40) [-40.0|6513.5] "C" Vector__XXX
 SG_ segment6Cell7Temperature_C : 39|16@0+ (0.1,-40) [-40.0|6513.5] "C" Vector__XXX
 SG_ segment6Cell8Temperature_C : 55|16@0+ (0.1,-40) [-40.0|6513.5] "C" Vector__XXX

BO_ 872 ID_872: 8 Vector__XXX
 SG_ segment6Cell9Temperature_C : 7|16@0+ (0.1,-40) [-40.0|6513.5] "C" Vector__XXX
 SG_ segment6Cell10Temperature_C : 23|16@0+ (0.1,-40) [-40.0|6513.5] "C" Vector__XXX
 SG_ segment6Cell11Temperature_C : 39|16@0+ (0.1,-40) [-40.0|6513.5] "C" Vector__XXX
 SG_ segment6Cell12Temperature_C : 55|16@0+ (0.1,-40) [-40.0|6513.5] "C" Vector__XXX

BO_ 873 ID_873: 8 Vector__XXX
 SG_ segment6Cell13Temperature_C : 7|16@0+ (0.1,-40) [-40.0|6513.5] "C" Vector__XXX
 SG_ segment6Cell14Temperature_C : 23|16@0+ (0.1,-40) [-40.0|6513.5] "C" Vector__XXX
 SG_ segment6Cell15Temperature_C : 39|16@0+ (0.1,-40) [-40.0|6513.5] "C" Vector__XXX
 SG_ segment6Cell16Temperature_C : 55|16@0+ (0.1,-40) [-40.0|6513.5] "C" Vector__XXX

BO_ 880 ID_880: 8 Vector__XXX
 SG_ segment7MaxCellVoltage_V : 7|16@0+ (0.001,0) [0.0|65.535] "V" Vector__XXX
 SG_ segment7MinCellVoltage_V : 23|16@0+ (0.001,0) [0.0|65.535] "V" Vector__XXX
 SG_ segment7AvgCellVoltage_V : 39|16@0+ (0.001,0) [0.0|65.535] "V" Vector__XXX
 SG_ segment7DieTemperature_C : 55|16@0+ (0.1,-40) [-40.0|6513.5] "C" Vector__XXX

BO_ 881 ID_881: 8 Vector__XXX
 SG_ segment7MaxCellTemperature_C : 7|16@0+ (0.1,-40) [-40.0|6513.5] "C" Vector__XXX
 SG_ segment7MinCellTemperature_C : 23|16@0+ (0.1,-40) [-40.0|6513.5] "C" Vector__XXX
 SG_ segment7AvgCellTemperature_C : 39|16@0+ (0.1,-40) [-40.0|6513.5] "C" Vector__XXX
 SG_ segment7BoardTemperature_C : 55|16@0+ (0.1,-40) [-40.0|6513.5] "C" Vector__XXX

BO_ 882 ID_882: 8 Vector__XXX
 SG_ segment7Cell1Voltage_V : 7|16@0+ (0.001,0) [0.0|65.535] "V" Vector__XXX
 SG_ segment7Cell2Voltage_V : 23|16@0+ (0.001,0) [0.0|65.535] "V" Vector__XXX
 SG_ segment7Cell3Voltage_V : 39|16@0+ (0.001,0) [0.0|65.535] "V" Vector__XXX
 SG_ segment7Cell4Voltage_V : 55|16@0+ (0.001,0) [0.0|65.535] "V" Vector__XXX

BO_ 883 ID_883: 8 Vector__XXX
 SG_ segment7Cell5Voltage_V : 7|16@0+ (0.001,0) [0.0|65.535] "V" Vector__XXX
 SG_ segment7Cell6Voltage_V : 23|16@0+ (0.001,0) [0.0|65.535] "V" Vector__XXX
 SG_ segment7Cell7Voltage_V : 39|16@0+ (0.001,0) [0.0|65.535] "V" Vector__XXX
 SG_ segment7Cell8Voltage_V : 55|16@0+ (0.001,0) [0.0|65.535] "V" Vector__XXX

BO_ 884 ID_884: 8 Vector__XXX
 SG_ segment7Cell9Voltage_V : 7|16@0+ (0.001,0) [0.0|65.535] "V" Vector__XXX
 SG_ segment7Cell10Voltage_V : 23|16@0+ (0.001,0) [0.0|65.535] "V" Vector__XXX
 SG_ segment7Cell11Voltage_V : 39|16@0+ (0.001,0) [0.0|65.535] "V" Vector__XXX
 SG_ segment7Cell12Voltage_V : 55|16@0+ (0.001,0) [0.0|65.535] "V" Vector__XXX

BO_ 885 ID_885: 8 Vector__XXX
 SG_ segment7Cell13Voltage_V : 7|16@0+ (0.001,0) [0.0|65.535] "V" Vector__XXX
 SG_ segment7Cell14Voltage_V : 23|16@0+ (0.001,0) [0.0|65.535] "V" Vector__XXX
 SG_ segment7Cell15Voltage_V : 39|16@0+ (0.001,0) [0.0|65.535] "V" Vector__XXX
 SG_ segment7Cell16Voltage_V : 55|16@0+ (0.001,0) [0.0|65.535] "V" Vector__XXX

BO_ 886 ID_886: 8 Vector__XXX
 SG_ segment7Cell1Temperature_C : 7|16@0+ (0.1,-40) [-40.0|6513.5] "C" Vector__XXX
 SG_ segment7Cell2Temperature_C : 23|16@0+ (0.1,-40) [-40.0|6513.5] "C" Vector__XXX
 SG_ segment7Cell3Temperature_C : 39|16@0+ (0.1,-40) [-40.0|6513.5] "C" Vector__XXX
 SG_ segment7Cell4Temperature_C : 55|16@0+ (0.1,-40) [-40.0|6513.5] "C" Vector__XXX

BO_ 887 ID_887: 8 Vector__XXX
 SG_ segment7Cell5Temperature_C : 7|16@0+ (0.1,-40) [-40.0|6513.5] "C" Vector__XXX
 SG_ segment7Cell6Temperature_C : 23|16@0+ (0.1,-40) [-40.0|6513.5] "C" Vector__XXX
 SG_ segment7Cell7Temperature_C : 39|16@0+ (0.1,-40) [-40.0|6513.5] "C" Vector__XXX
 SG_ segment7Cell8Temperature_C : 55|16@0+ (0.1,-40) [-40.0|6513.5] "C" Vector__XXX

BO_ 888 ID_888: 8 Vector__XXX
 SG_ segment7Cell9Temperature_C : 7|16@0+ (0.1,-40) [-40.0|6513.5] "C" Vector__XXX
 SG_ segment7Cell10Temperature_C : 23|16@0+ (0.1,-40) [-40.0|6513.5] "C" Vector__XXX
 SG_ segment7Cell11Temperature_C : 39|16@0+ (0.1,-40) [-40.0|6513.5] "C" Vector__XXX
 SG_ segment7Cell12Temperature_C : 55|16@0+ (0.1,-40) [-40.0|6513.5] "C" Vector__XXX

BO_ 889 ID_889: 8 Vector__XXX
 SG_ segment7Cell13Temperature_C : 7|16@0+ (0.1,-40) [-40.0|6513.5] "C" Vector__XXX
 SG_ segment7Cell14Temperature_C : 23|16@0+ (0.1,-40) [-40.0|6513.5] "C" Vector__XXX
 SG_ segment7Cell15Temperature_C : 39|16@0+ (0.1,-40) [-40.0|6513.5] "C" Vector__XXX
 SG_ segment7Cell16Temperature_C : 55|16@0+ (0.1,-40) [-40.0|6513.5] "C" Vector__XXX

BO_ 896 ID_896: 8 Vector__XXX
 SG_ segment8MaxCellVoltage_V : 7|16@0+ (0.001,0) [0.0|65.535] "V" Vector__XXX
 SG_ segment8MinCellVoltage_V : 23|16@0+ (0.001,0) [0.0|65.535] "V" Vector__XXX
 SG_ segment8AvgCellVoltage_V : 39|16@0+ (0.001,0) [0.0|65.535] "V" Vector__XXX
 SG_ segment8DieTemperature_C : 55|16@0+ (0.1,-40) [-40.0|6513.5] "C" Vector__XXX

BO_ 897 ID_897: 8 Vector__XXX
 SG_ segment8MaxCellTemperature_C : 7|16@0+ (0.1,-40) [-40.0|6513.5] "C" Vector__XXX
 SG_ segment8MinCellTemperature_C : 23|16@0+ (0.1,-40) [-40.0|6513.5] "C" Vector__XXX
 SG_ segment8AvgCellTemperature_C : 39|16@0+ (0.1,-40) [-40.0|6513.5] "C" Vector__XXX
 SG_ segment8BoardTemperature_C : 55|16@0+ (0.1,-40) [-40.0|6513.5] "C" Vector__XXX

BO_ 898 ID_898: 8 Vector__XXX
 SG_ segment8Cell1Voltage_V : 7|16@0+ (0.001,0) [0.0|65.535] "V" Vector__XXX
 SG_ segment8Cell2Voltage_V : 23|16@0+ (0.001,0) [0.0|65.535] "V" Vector__XXX
 SG_ segment8Cell3Voltage_V : 39|16@0+ (0.001,0) [0.0|65.535] "V" Vector__XXX
 SG_ segment8Cell4Voltage_V : 55|16@0+ (0.001,0) [0.0|65.535] "V" Vector__XXX

BO_ 899 ID_899: 8 Vector__XXX
 SG_ segment8Cell5Voltage_V : 7|16@0+ (0.001,0) [0.0|65.535] "V" Vector__XXX
 SG_ segment8Cell6Voltage_V : 23|16@0+ (0.001,0) [0.0|65.535] "V" Vector__XXX
 SG_ segment8Cell7Voltage_V : 39|16@0+ (0.001,0) [0.0|65.535] "V" Vector__XXX
 SG_ segment8Cell8Voltage_V : 55|16@0+ (0.001,0) [0.0|65.535] "V" Vector__XXX

BO_ 900 ID_900: 8 Vector__XXX
 SG_ segment8Cell9Voltage_V : 7|16@0+ (0.001,0) [0.0|65.535] "V" Vector__XXX
 SG_ segment8Cell10Voltage_V : 23|16@0+ (0.001,0) [0.0|65.535] "V" Vector__XXX
 SG_ segment8Cell11Voltage_V : 39|16@0+ (0.001,0) [0.0|65.535] "V" Vector__XXX
 SG_ segment8Cell12Voltage_V : 55|16@0+ (0.001,0) [0.0|65.535] "V" Vector__XXX

BO_ 901 ID_901: 8 Vector__XXX
 SG_ segment8Cell13Voltage_V : 7|16@0+ (0.001,0) [0.0|65.535] "V" Vector__XXX
 SG_ segment8Cell14Voltage_V : 23|16@0+ (0.001,0) [0.0|65.535] "V" Vector__XXX
 SG_ segment8Cell15Voltage_V : 39|16@0+ (0.001,0) [0.0|65.535] "V" Vector__XXX
 SG_ segment8Cell16Voltage_V : 55|16@0+ (0.001,0) [0.0|65.535] "V" Vector__XXX

BO_ 902 ID_902: 8 Vector__XXX
 SG_ segment8Cell1Temperature_C : 7|16@0+ (0.1,-40) [-40.0|6513.5] "C" Vector__XXX
 SG_ segment8Cell2Temperature_C : 23|16@0+ (0.1,-40) [-40.0|6513.5] "C" Vector__XXX
 SG_ segment8Cell3Temperature_C : 39|16@0+ (0.1,-40) [-40.0|6513.5] "C" Vector__XXX
 SG_ segment8Cell4Temperature_C : 55|16@0+ (0.1,-40) [-40.0|6513.5] "C" Vector__XXX

BO_ 903 ID_903: 8 Vector__XXX
 SG_ segment8Cell5Temperature_C : 7|16@0+ (0.1,-40) [-40.0|6513.5] "C" Vector__XXX
 SG_ segment8Cell6Temperature_C : 23|16@0+ (0.1,-40) [-40.0|6513.5] "C" Vector__XXX
 SG_ segment8Cell7Temperature_C : 39|16@0+ (0.1,-40) [-40.0|6513.5] "C" Vector__XXX
 SG_ segment8Cell8Temperature_C : 55|16@0+ (0.1,-40) [-40.0|6513.5] "C" Vector__XXX

BO_ 904 ID_904: 8 Vector__XXX
 SG_ segment8Cell9Temperature_C : 7|16@0+ (0.1,-40) [-40.0|6513.5] "C" Vector__XXX
 SG_ segment8Cell10Temperature_C : 23|16@0+ (0.1,-40) [-40.0|6513.5] "C" Vector__XXX
 SG_ segment8Cell11Temperature_C : 39|16@0+ (0.1,-40) [-40.0|6513.5] "C" Vector__XXX
 SG_ segment8Cell12Temperature_C : 55|16@0+ (0.1,-40) [-40.0|6513.5] "C" Vector__XXX

BO_ 905 ID_905: 8 Vector__XXX
 SG_ segment8Cell13Temperature_C : 7|16@0+ (0.1,-40) [-40.0|6513.5] "C" Vector__XXX
 SG_ segment8Cell14Temperature_C : 23|16@0+ (0.1,-40) [-40.0|6513.5] "C" Vector__XXX
 SG_ segment8Cell15Temperature_C : 39|16@0+ (0.1,-40) [-40.0|6513.5] "C" Vector__XXX
 SG_ segment8Cell16Temperature_C : 55|16@0+ (0.1,-40) [-40.0|6513.5] "C" Vector__XXX

BO_ 912 ID_912: 8 Vector__XXX
 SG_ chargerVoltageSetPoint_V : 7|16@0+ (0.1,0) [0.0|6553.5] "V" Vector__XXX
 SG_ chargerCurrentSetPoint_A : 23|16@0+ (0.1,0) [0.0|6553.5] "A" Vector__XXX
 SG_ chargerStatusByte : 39|8@0+ (1,0) [0|255] "" Vector__XXX

BO_ 0 ID_0: 8 Vector__XXX
 SG_ vbatChan0Current_A : 7|16@0+ (0.00741391941,0) [0.0|485.87120853435] "V" Vector__XXX
 SG_ vbatChan1Current_A : 23|16@0+ (0.00741391941,0) [0.0|485.87120853435] "V" Vector__XXX
 SG_ vbatChan2Current_A : 39|16@0+ (0.00741391941,0) [0.0|485.87120853435] "V" Vector__XXX
 SG_ vbatChan3Current_A : 55|16@0+ (0.00741391941,0) [0.0|485.87120853435] "V" Vector__XXX

BO_ 1 ID_1: 8 Vector__XXX
 SG_ vbatChan4Current_A : 7|16@0+ (0.00741391941,0) [0.0|485.87120853435] "V" Vector__XXX
 SG_ vbatChan5Current_A : 23|16@0+ (0.00741391941,0) [0.0|485.87120853435] "V" Vector__XXX
 SG_ vbatChan6Current_A : 39|16@0+ (0.00741391941,0) [0.0|485.87120853435] "V" Vector__XXX
 SG_ fiveVChan0Current_A : 55|16@0+ (0.00196141636,0) [0.0|128.5414211526] "V" Vector__XXX

BO_ 2 ID_2: 8 Vector__XXX
 SG_ fiveVChan1Current_A : 7|16@0+ (0.00196141636,0) [0.0|128.5414211526] "V" Vector__XXX
 SG_ fiveVChan2Current_A : 23|16@0+ (0.00196141636,0) [0.0|128.5414211526] "V" Vector__XXX
 SG_ fiveVChan3Current_A : 39|16@0+ (0.00196141636,0) [0.0|128.5414211526] "V" Vector__XXX
 SG_ can0Utilization_percent : 55|16@0+ (0.1,0) [0.0|6553.5] "%" Vector__XXX

BO_ 3 ID_3: 8 Vector__XXX
 SG_ can1Utilization_percent : 7|16@0+ (0.1,0) [0.0|6553.5] "%" Vector__XXX
 SG_ can2Utilization_percent : 23|16@0+ (0.1,0) [0.0|6553.5] "%" Vector__XXX
 SG_ plmVbatVoltage_V : 39|16@0+ (0.00506178266,0) [0.0|331.7239266231] "V" Vector__XXX
 SG_ plm5VVoltage_V : 55|16@0+ (0.00195457875,0) [0.0|128.09331838125] "V" Vector__XXX

BO_ 4 ID_4: 8 Vector__XXX
 SG_ packetsLogged_ul : 7|32@0+ (1,0) [0|4294967295] "" Vector__XXX
 SG_ packetsDropped_ul : 39|32@0+ (1,0) [0|4294967295] "" Vector__XXX

BO_ 5 ID_5: 8 Vector__XXX
 SG_ storageBufferFill_percent : 7|16@0+ (0.1,0) [0.0|6553.5] "%" Vector__XXX
 SG_ telemetryBufferFill_percent : 23|16@0+ (0.1,0) [0.0|6553.5] "%" Vector__XXX

BO_ 6 ID_6: 8 Vector__XXX
 SG_ PLM_Temp_degrees : 7|16@0+ (0.002518,-40) [-40.0|125.01712999999998] "C" Vector__XXX
 SG_ PLM_Humidity_percent : 23|16@0+ (0.024414,0) [0.0|1599.9714900000001] "%" Vector__XXX
 SG_ PLM_Micro_Temp : 39|16@0+ (0.024414,0) [0.0|1599.9714900000001] "%" Vector__XXX

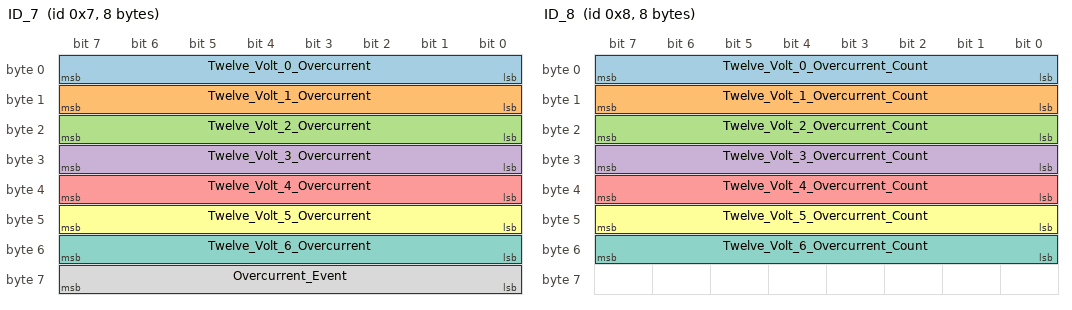
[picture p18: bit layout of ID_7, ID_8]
BO_ 7 ID_7: 8 Vector__XXX
 SG_ Twelve_Volt_0_Overcurrent : 7|8@0+ (1,0) [0|255] "" Vector__XXX
 SG_ Twelve_Volt_1_Overcurrent : 15|8@0+ (1,0) [0|255] "" Vector__XXX
 SG_ Twelve_Volt_2_Overcurrent : 23|8@0+ (1,0) [0|255] "" Vector__XXX
 SG_ Twelve_Volt_3_Overcurrent : 31|8@0+ (1,0) [0|255] "" Vector__XXX
 SG_ Twelve_Volt_4_Overcurrent : 39|8@0+ (1,0) [0|255] "" Vector__XXX
 SG_ Twelve_Volt_5_Overcurrent : 47|8@0+ (1,0) [0|255] "" Vector__XXX
 SG_ Twelve_Volt_6_Overcurrent : 55|8@0+ (1,0) [0|255] "" Vector__XXX
 SG_ Overcurrent_Event : 63|8@0+ (1,0) [0|255] "" Vector__XXX

BO_ 8 ID_8: 8 Vector__XXX
 SG_ Twelve_Volt_0_Overcurrent_Count : 7|8@0+ (1,0) [0|255] "" Vector__XXX
 SG_ Twelve_Volt_1_Overcurrent_Count : 15|8@0+ (1,0) [0|255] "" Vector__XXX
 SG_ Twelve_Volt_2_Overcurrent_Count : 23|8@0+ (1,0) [0|255] "" Vector__XXX
 SG_ Twelve_Volt_3_Overcurrent_Count : 31|8@0+ (1,0) [0|255] "" Vector__XXX
 SG_ Twelve_Volt_4_Overcurrent_Count : 39|8@0+ (1,0) [0|255] "" Vector__XXX
 SG_ Twelve_Volt_5_Overcurrent_Count : 47|8@0+ (1,0) [0|255] "" Vector__XXX
 SG_ Twelve_Volt_6_Overcurrent_Count : 55|8@0+ (1,0) [0|255] "" Vector__XXX

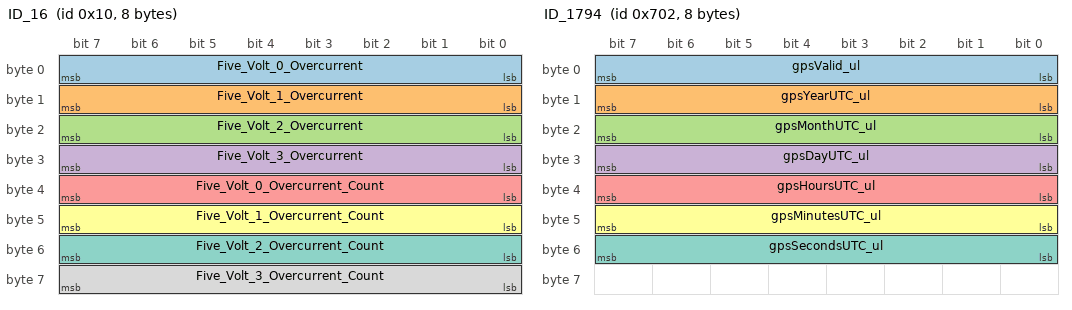
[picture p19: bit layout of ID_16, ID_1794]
BO_ 16 ID_16: 8 Vector__XXX
 SG_ Five_Volt_0_Overcurrent : 7|8@0+ (1,0) [0|255] "" Vector__XXX
 SG_ Five_Volt_1_Overcurrent : 15|8@0+ (1,0) [0|255] "" Vector__XXX
 SG_ Five_Volt_2_Overcurrent : 23|8@0+ (1,0) [0|255] "" Vector__XXX
 SG_ Five_Volt_3_Overcurrent : 31|8@0+ (1,0) [0|255] "" Vector__XXX
 SG_ Five_Volt_0_Overcurrent_Count : 39|8@0+ (1,0) [0|255] "" Vector__XXX
 SG_ Five_Volt_1_Overcurrent_Count : 47|8@0+ (1,0) [0|255] "" Vector__XXX
 SG_ Five_Volt_2_Overcurrent_Count : 55|8@0+ (1,0) [0|255] "" Vector__XXX
 SG_ Five_Volt_3_Overcurrent_Count : 63|8@0+ (1,0) [0|255] "" Vector__XXX

BO_ 1792 ID_1792: 8 Vector__XXX
 SG_ gpsLatitude_deg : 7|32@0+ (2.1457672119140625e-05,0) [0.0|92159.99997854233] "deg" Vector__XXX
 SG_ gpsLongitude_deg : 39|32@0+ (2.1457672119140625e-05,0) [0.0|92159.99997854233] "deg" Vector__XXX

BO_ 1793 ID_1793: 8 Vector__XXX
 SG_ gpsSpeed_mph : 7|16@0+ (0.01,0) [0.0|655.35] "mph" Vector__XXX
 SG_ gpsAltitude_ft : 23|16@0+ (1,0) [0|65535] "ft" Vector__XXX
 SG_ gpsCourse_deg : 39|16@0+ (0.01,0) [0.0|655.35] "deg" Vector__XXX
 SG_ gpsSatelliteCount_ul : 55|8@0+ (1,0) [0|255] "" Vector__XXX

BO_ 1794 ID_1794: 8 Vector__XXX
 SG_ gpsValid_ul : 7|8@0+ (1,0) [0|255] "" Vector__XXX
 SG_ gpsYearUTC_ul : 15|8@0+ (1,0) [0|255] "" Vector__XXX
 SG_ gpsMonthUTC_ul : 23|8@0+ (1,0) [0|255] "" Vector__XXX
 SG_ gpsDayUTC_ul : 31|8@0+ (1,0) [0|255] "" Vector__XXX
 SG_ gpsHoursUTC_ul : 39|8@0+ (1,0) [0|255] "" Vector__XXX
 SG_ gpsMinutesUTC_ul : 47|8@0+ (1,0) [0|255] "" Vector__XXX
 SG_ gpsSecondsUTC_ul : 55|8@0+ (1,0) [0|255] "" Vector__XXX

BO_ 112 ID_112: 8 Vector__XXX
 SG_ yawRate_degPerSec : 0|16@1+ (0.005,-163.84) [-163.84|163.835] "deg/s" Vector__XXX
 SG_ lateralAccel_G : 32|16@1+ (0.0001274,-4.1746432) [-4.1746432|4.1745158] "G" Vector__XXX

BO_ 128 ID_128: 8 Vector__XXX
 SG_ rollRate_degPerSec : 0|16@1+ (0.005,-163.84) [-163.84|163.835] "deg/s" Vector__XXX
 SG_ longitudinalAccel_G : 32|16@1+ (0.0001274,-4.1746432) [-4.1746432|4.1745158] "G" Vector__XXX

BO_ 1398 ID_1398: 8 Vector__XXX
 SG_ verticalAccel_G : 32|16@1+ (0.0001274,-4.1746432) [-4.1746432|4.1745158] "G" Vector__XXX

BO_ 229 ID_229: 8 Vector__XXX
 SG_ lapBeaconRaw_ul : 7|24@0+ (1,0) [0|16777215] "" Vector__XXX

BO_ 230 ID_230: 8 Vector__XXX
 SG_ lapBeacon_ul : 7|8@0+ (1,0) [0|255] "" Vector__XXX

BO_ 1200 ID_1200: 8 Vector__XXX
 SG_ rearRightTireTempCh1 : 7|16@0+ (0.1,-100.0) [-100.0|6453.5] "C" Vector__XXX

BO_ 1201 ID_1201: 8 Vector__XXX
 SG_ rearRightTireTempCh5 : 7|16@0+ (0.1,-100.0) [-100.0|6453.5] "C" Vector__XXX
 SG_ rearRightTireTempCh7 : 39|16@0+ (0.1,-100.0) [-100.0|6453.5] "C" Vector__XXX
 SG_ rearRightTireTempCh8 : 55|16@0+ (0.1,-100.0) [-100.0|6453.5] "C" Vector__XXX

BO_ 1202 ID_1202: 8 Vector__XXX
 SG_ rearRightTireTempCh9 : 7|16@0+ (0.1,-100.0) [-100.0|6453.5] "C" Vector__XXX
 SG_ rearRightTireTempCh10 : 23|16@0+ (0.1,-100.0) [-100.0|6453.5] "C" Vector__XXX
 SG_ rearRightTireTempCh12 : 55|16@0+ (0.1,-100.0) [-100.0|6453.5] "C" Vector__XXX

BO_ 1203 ID_1203: 8 Vector__XXX
 SG_ rearRightTireTempCh16 : 55|16@0+ (0.1,-100.0) [-100.0|6453.5] "C" Vector__XXX

BO_ 1208 ID_1208: 8 Vector__XXX
 SG_ frontRightTireTempCh1 : 7|16@0+ (0.1,-100.0) [-100.0|6453.5] "C" Vector__XXX

BO_ 1209 ID_1209: 8 Vector__XXX
 SG_ frontRightTireTempCh5 : 7|16@0+ (0.1,-100.0) [-100.0|6453.5] "C" Vector__XXX
 SG_ frontRightTireTempCh7 : 39|16@0+ (0.1,-100.0) [-100.0|6453.5] "C" Vector__XXX
 SG_ frontRightTireTempCh8 : 55|16@0+ (0.1,-100.0) [-100.0|6453.5] "C" Vector__XXX

BO_ 1210 ID_1210: 8 Vector__XXX
 SG_ frontRightTireTempCh9 : 7|16@0+ (0.1,-100.0) [-100.0|6453.5] "C" Vector__XXX
 SG_ frontRightTireTempCh10 : 23|16@0+ (0.1,-100.0) [-100.0|6453.5] "C" Vector__XXX
 SG_ frontRightTireTempCh12 : 55|16@0+ (0.1,-100.0) [-100.0|6453.5] "C" Vector__XXX

BO_ 1211 ID_1211: 8 Vector__XXX
 SG_ frontRightTireTempCh16 : 55|16@0+ (0.1,-100.0) [-100.0|6453.5] "C" Vector__XXX

BO_ 1212 ID_1212: 8 Vector__XXX
 SG_ frontLeftTireTempCh1 : 7|16@0+ (0.1,-100.0) [-100.0|6453.5] "C" Vector__XXX

BO_ 1213 ID_1213: 8 Vector__XXX
 SG_ frontLeftTireTempCh5 : 7|16@0+ (0.1,-100.0) [-100.0|6453.5] "C" Vector__XXX
 SG_ frontLeftTireTempCh7 : 39|16@0+ (0.1,-100.0) [-100.0|6453.5] "C" Vector__XXX
 SG_ frontLeftTireTempCh8 : 55|16@0+ (0.1,-100.0) [-100.0|6453.5] "C" Vector__XXX

BO_ 1214 ID_1214: 8 Vector__XXX
 SG_ frontLeftTireTempCh9 : 7|16@0+ (0.1,-100.0) [-100.0|6453.5] "C" Vector__XXX
 SG_ frontLeftTireTempCh10 : 23|16@0+ (0.1,-100.0) [-100.0|6453.5] "C" Vector__XXX
 SG_ frontLeftTireTempCh12 : 55|16@0+ (0.1,-100.0) [-100.0|6453.5] "C" Vector__XXX

BO_ 1215 ID_1215: 8 Vector__XXX
 SG_ frontLeftTireTempCh16 : 55|16@0+ (0.1,-100.0) [-100.0|6453.5] "C" Vector__XXX

BO_ 1204 ID_1204: 8 Vector__XXX
 SG_ rearLeftTireTempCh1 : 7|16@0+ (0.1,-100.0) [-100.0|6453.5] "C" Vector__XXX

BO_ 1205 ID_1205: 8 Vector__XXX
 SG_ rearLeftTireTempCh5 : 7|16@0+ (0.1,-100.0) [-100.0|6453.5] "C" Vector__XXX
 SG_ rearLeftTireTempCh7 : 39|16@0+ (0.1,-100.0) [-100.0|6453.5] "C" Vector__XXX
 SG_ rearLeftTireTempCh8 : 55|16@0+ (0.1,-100.0) [-100.0|6453.5] "C" Vector__XXX

BO_ 1206 ID_1206: 8 Vector__XXX
 SG_ rearLeftTireTempCh9 : 7|16@0+ (0.1,-100.0) [-100.0|6453.5] "C" Vector__XXX
 SG_ rearLeftTireTempCh10 : 23|16@0+ (0.1,-100.0) [-100.0|6453.5] "C" Vector__XXX
 SG_ rearLeftTireTempCh12 : 55|16@0+ (0.1,-100.0) [-100.0|6453.5] "C" Vector__XXX

BO_ 1207 ID_1207: 8 Vector__XXX
 SG_ rearLeftTireTempCh16 : 55|16@0+ (0.1,-100.0) [-100.0|6453.5] "C" Vector__XXX

BO_ 1872 ID_1872: 8 Vector__XXX
 SG_ tm_CAN1Util_percent : 7|16@0+ (0.1,0) [0.0|6553.5] "%" Vector__XXX
 SG_ tm_CAN2Util_percent : 23|16@0+ (0.1,0) [0.0|6553.5] "%" Vector__XXX
 SG_ tm_SDBufferFill_percent : 39|16@0+ (0.1,0) [0.0|6553.5] "%" Vector__XXX
 SG_ tm_RadioBufferFill_percent : 55|16@0+ (0.1,0) [0.0|6553.5] "%" Vector__XXX

BO_ 1873 ID_1873: 8 Vector__XXX
 SG_ tm_SDBytesTransferred_bytes : 7|32@0+ (1,0) [0|4294967295] "" Vector__XXX
 SG_ tm_RadioBytesTransferred_bytes : 39|32@0+ (1,0) [0|4294967295] "" Vector__XXX

BO_ 1874 ID_1874: 8 Vector__XXX
 SG_ tm_SDPacketsDropped_ul : 7|32@0+ (1,0) [0|4294967295] "" Vector__XXX
 SG_ tm_RadioPacketsDropped_ul : 39|32@0+ (1,0) [0|4294967295] "" Vector__XXX

BO_ 1875 ID_1875: 8 Vector__XXX
 SG_ tm_CoinBattery_V : 7|16@0+ (0.01,0) [0.0|655.35] "V" Vector__XXX

BO_ 1876 ID_1876: 8 Vector__XXX
 SG_ sdcStatus17 : 7|8@0+ (1,0) [0|255] "" Vector__XXX
 SG_ sdcStatus18 : 15|8@0+ (1,0) [0|255] "" Vector__XXX
 SG_ sdcStatus19 : 23|8@0+ (1,0) [0|255] "" Vector__XXX

BO_ 1877 ID_1877: 8 Vector__XXX
 SG_ chargingPowerLimit : 7|16@0+ (1,0) [0|65535] "" Vector__XXX
 SG_ forceEnableBalancing_state : 23|8@0+ (1,0) [0|255] "" Vector__XXX

BO_ 1878 ID_1878: 8 Vector__XXX
 SG_ sdcStatus5 : 7|16@0+ (1,0) [0|65535] "" Vector__XXX
 SG_ sdcStatus6 : 23|16@0+ (1,0) [0|65535] "" Vector__XXX
 SG_ sdcStatus7 : 39|16@0+ (1,0) [0|65535] "" Vector__XXX
